VERSION ""
NS_ :

BS_:

BU_: Debug Boot INVR PDM FSM DIM BMS INVL DCM DEBUG

BO_ 701 Debug_CanMode: 1 Debug
SG_ Debug_EnableDebugMode : 0|1@1+ (1,0) [0|1] "" DEBUG,PDM,FSM,DIM,BMS,DCM

BO_ 702 Debug_Charging: 1 Debug
SG_ Debug_StartCharging : 0|1@1+ (1,0) [0|1] "" DEBUG,BMS

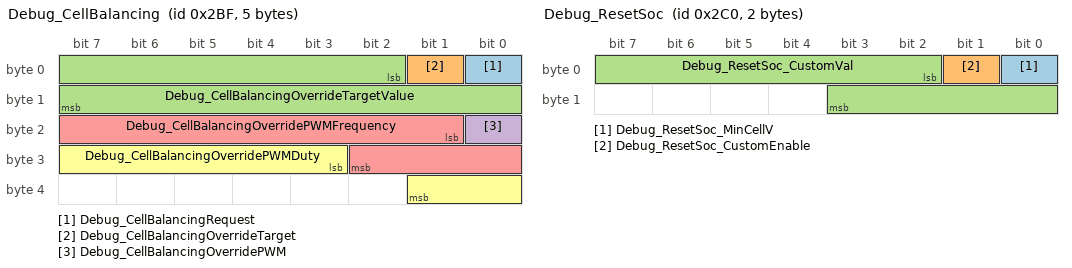
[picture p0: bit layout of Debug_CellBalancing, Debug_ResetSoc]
BO_ 703 Debug_CellBalancing: 5 Debug
SG_ Debug_CellBalancingRequest : 0|1@1+ (1,0) [0|1] "" DEBUG,BMS
SG_ Debug_CellBalancingOverrideTarget : 1|1@1+ (1,0) [0|1] "" DEBUG,BMS
SG_ Debug_CellBalancingOverrideTargetValue : 2|14@1+ (0.0001,3) [3|4.2] "V" DEBUG,BMS
SG_ Debug_CellBalancingOverridePWM : 16|1@1+ (1,0) [0|1] "" DEBUG,BMS
SG_ Debug_CellBalancingOverridePWMFrequency : 17|10@1+ (0.1,0) [0|100] "Hz" DEBUG,BMS
SG_ Debug_CellBalancingOverridePWMDuty : 27|7@1+ (1,0) [0|100] "%" DEBUG,BMS

BO_ 704 Debug_ResetSoc: 2 Debug
SG_ Debug_ResetSoc_MinCellV : 0|1@1+ (1,0) [0|1] "" DEBUG,BMS
SG_ Debug_ResetSoc_CustomEnable : 1|1@1+ (1,0) [0|1] "" DEBUG,BMS
SG_ Debug_ResetSoc_CustomVal : 2|10@1+ (0.1,0) [0|100] "%" DEBUG,BMS

BO_ 1109 Boot_BMS: 1 Boot
SG_ Boot_BMS_Status : 0|2@1+ (1,0) [0|2] "" DEBUG

BO_ 1119 Boot_DCM: 1 Boot
SG_ Boot_DCM_Status : 0|2@1+ (1,0) [0|2] "" DEBUG

BO_ 1129 Boot_FSM: 1 Boot
SG_ Boot_FSM_Status : 0|2@1+ (1,0) [0|2] "" DEBUG

BO_ 1139 Boot_PDM: 1 Boot
SG_ Boot_PDM_Status : 0|2@1+ (1,0) [0|2] "" DEBUG

BO_ 1149 Boot_DIM: 1 Boot
SG_ Boot_DIM_Status : 0|2@1+ (1,0) [0|2] "" DEBUG

BO_ 1309 Boot_H7Dev: 1 Boot
SG_ Boot_H7Dev_Status : 0|2@1+ (1,0) [0|2] "" DEBUG

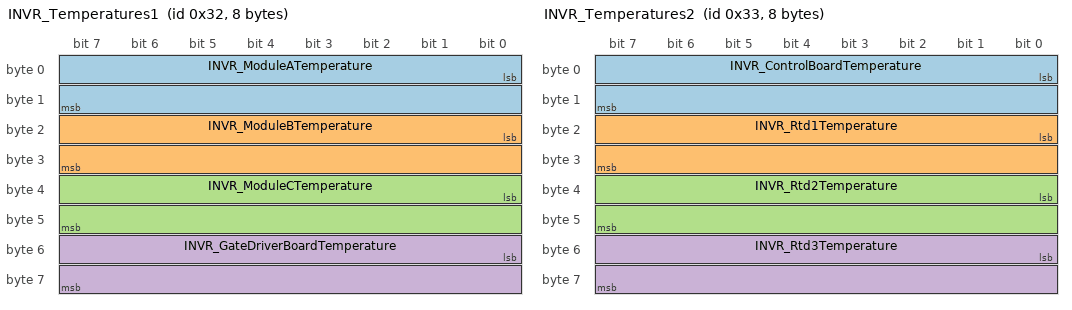
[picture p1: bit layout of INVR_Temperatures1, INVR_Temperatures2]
BO_ 50 INVR_Temperatures1: 8 INVR
SG_ INVR_ModuleATemperature : 0|16@1- (0.1,0) [-3276.8|3276.7] "degC" DEBUG,DIM
SG_ INVR_ModuleBTemperature : 16|16@1- (0.1,0) [-3276.8|3276.7] "degC" DEBUG,DIM
SG_ INVR_ModuleCTemperature : 32|16@1- (0.1,0) [-3276.8|3276.7] "degC" DEBUG,DIM
SG_ INVR_GateDriverBoardTemperature : 48|16@1- (0.1,0) [-3276.8|3276.7] "degC" DEBUG,DIM

BO_ 51 INVR_Temperatures2: 8 INVR
SG_ INVR_ControlBoardTemperature : 0|16@1- (0.1,0) [-3276.8|3276.7] "degC" DEBUG
SG_ INVR_Rtd1Temperature : 16|16@1- (0.1,0) [-3276.8|3276.7] "degC" DEBUG
SG_ INVR_Rtd2Temperature : 32|16@1- (0.1,0) [-3276.8|3276.7] "degC" DEBUG
SG_ INVR_Rtd3Temperature : 48|16@1- (0.1,0) [-3276.8|3276.7] "degC" DEBUG

BO_ 52 INVR_Temperatures3: 8 INVR
SG_ INVR_Rtd4Temperature : 0|16@1- (0.1,0) [-3276.8|3276.7] "degC" DEBUG,DCM
SG_ INVR_Rtd5Temperature : 16|16@1- (0.1,0) [-3276.8|3276.7] "degC" DEBUG,DCM
SG_ INVR_MotorTemperature : 32|16@1- (0.1,0) [-3276.8|3276.7] "degC" DEBUG,DCM
SG_ INVR_TorqueShudder : 48|16@1- (0.1,0) [-3276.8|3276.7] "Nm" DEBUG,DCM

BO_ 55 INVR_MotorPositionInfo: 8 INVR
SG_ INVR_MotorAngle : 0|16@1- (0.1,0) [0.0|359.9] "deg" DEBUG,DIM,DCM
SG_ INVR_MotorSpeed : 16|16@1- (1,0) [-32768|32767] "rpm" DEBUG,DIM,DCM
SG_ INVR_ElectricalOutputFrequency : 32|16@1- (0.1,0) [-3276.8|3276.7] "hz" DEBUG,DIM,DCM
SG_ INVR_DeltaResolverFiltered : 48|16@1- (0.1,0) [0.0|359.9] "deg" DEBUG,DIM,DCM

BO_ 56 INVR_CurrentInfo: 8 INVR
SG_ INVR_PhaseACurrent : 0|16@1- (0.1,0) [-3276.8|3276.7] "A" DEBUG
SG_ INVR_PhaseBCurrent : 16|16@1- (0.1,0) [-3276.8|3276.7] "A" DEBUG
SG_ INVR_PhaseCCurrent : 32|16@1- (0.1,0) [-3276.8|3276.7] "A" DEBUG
SG_ INVR_DcBusCurrent : 48|16@1- (0.1,0) [-3276.8|3276.7] "A" DEBUG

BO_ 57 INVR_VoltageInfo: 8 INVR
SG_ INVR_DcBusVoltage : 0|16@1- (0.1,0) [-3276.8|3276.7] "V" DEBUG
SG_ INVR_OutputVoltage : 16|16@1- (0.1,0) [-3276.8|3276.7] "V" DEBUG
SG_ INVR_VAB_Vd_Voltage : 32|16@1- (0.1,0) [-3276.8|3276.7] "V" DEBUG
SG_ INVR_VBC_Vq_Voltage : 48|16@1- (0.1,0) [-3276.8|3276.7] "V" DEBUG

BO_ 59 INVR_InternalVoltages: 8 INVR
SG_ INVR_ReferenceVoltage_1V5 : 0|16@1- (0.01,0) [-327.68|327.67] "V" DEBUG
SG_ INVR_ReferenceVoltage_2V5 : 16|16@1- (0.01,0) [-327.68|327.67] "V" DEBUG
SG_ INVR_ReferenceVoltage_5V : 32|16@1- (0.01,0) [-327.68|327.67] "V" DEBUG
SG_ INVR_ReferenceVoltage_12V : 48|16@1- (0.01,0) [-327.68|327.67] "V" DEBUG

BO_ 60 INVR_InternalStates: 8 INVR
SG_ INVR_VsmState : 0|4@1+ (1,0) [0|15] "" DEBUG,DCM
SG_ INVR_PwmFrequency : 8|8@1+ (1,0) [0|255] "kHz" DEBUG,DCM
SG_ INVR_InverterState : 16|4@1+ (1,0) [0|9] "" DEBUG,DCM
SG_ INVR_Relay1State : 24|1@1+ (1,0) [0|1] "" DEBUG,DCM
SG_ INVR_Relay2State : 25|1@1+ (1,0) [0|1] "" DEBUG,DCM
SG_ INVR_Relay3State : 26|1@1+ (1,0) [0|1] "" DEBUG,DCM
SG_ INVR_Relay4State : 27|1@1+ (1,0) [0|1] "" DEBUG,DCM
SG_ INVR_Relay5State : 28|1@1+ (1,0) [0|1] "" DEBUG,DCM
SG_ INVR_Relay6State : 29|1@1+ (1,0) [0|1] "" DEBUG,DCM
SG_ INVR_InverterRunMode : 32|1@1+ (1,0) [0|1] "" DEBUG,DCM
SG_ INVR_InverterActiveDischargeState : 37|3@1+ (1,0) [0|4] "" DEBUG,DCM
SG_ INVR_InverterCommandMode : 40|1@1+ (1,0) [0|1] "" DEBUG,DCM
SG_ INVR_RollingCounter : 44|4@1+ (1,0) [0|15] "" DEBUG,DCM
SG_ INVR_InverterEnableState : 48|1@1+ (1,0) [0|1] "" DEBUG,DCM
SG_ INVR_StartModeActive : 54|1@1+ (1,0) [0|1] "" DEBUG,DCM
SG_ INVR_InverterLockoutEnabled : 55|1@1+ (1,0) [0|1] "" DEBUG,DCM
SG_ INVR_DirectionCommand : 56|1@1+ (1,0) [0|1] "" DEBUG,DCM
SG_ INVR_BmsActive : 57|1@1+ (1,0) [0|1] "" DEBUG,DCM
SG_ INVR_BmsTorqueLimiting : 58|1@1+ (1,0) [0|1] "" DEBUG,DCM
SG_ INVR_MaxSpeedLimiting : 59|1@1+ (1,0) [0|1] "" DEBUG,DCM
SG_ INVR_HotSpotLimiting : 60|1@1+ (1,0) [0|1] "" DEBUG,DCM
SG_ INVR_LowSpeedLimiting : 61|1@1+ (1,0) [0|1] "" DEBUG,DCM
SG_ INVR_CoolantTemperatureLimiting : 62|1@1+ (1,0) [0|1] "" DEBUG,DCM

BO_ 61 INVR_FaultCodes: 8 INVR
SG_ INVR_Post_HardwareGateDesaturationFault : 0|1@1+ (1,0) [0|1] "" DEBUG
SG_ INVR_Post_HwOverCurrentFault : 1|1@1+ (1,0) [0|1] "" DEBUG
SG_ INVR_Post_AcceleratorShorted : 2|1@1+ (1,0) [0|1] "" DEBUG
SG_ INVR_Post_AcceleratorOpen : 3|1@1+ (1,0) [0|1] "" DEBUG
SG_ INVR_Post_CurrentSensorLow : 4|1@1+ (1,0) [0|1] "" DEBUG
SG_ INVR_Post_CurrentSensorHigh : 5|1@1+ (1,0) [0|1] "" DEBUG
SG_ INVR_Post_ModuleTempreatureLow : 6|1@1+ (1,0) [0|1] "" DEBUG
SG_ INVR_Post_ModuleTemperatureHigh : 7|1@1+ (1,0) [0|1] "" DEBUG
SG_ INVR_Post_ControlPcbTemperatureLow : 8|1@1+ (1,0) [0|1] "" DEBUG
SG_ INVR_Post_ControlPcbTemperatureHigh : 9|1@1+ (1,0) [0|1] "" DEBUG
SG_ INVR_Post_GateDrivePcbTemperatureLow : 10|1@1+ (1,0) [0|1] "" DEBUG
SG_ INVR_Post_GateDrivePcbTemperatureHigh : 11|1@1+ (1,0) [0|1] "" DEBUG
SG_ INVR_Post_5VSenseVoltageLow : 12|1@1+ (1,0) [0|1] "" DEBUG
SG_ INVR_Post_5VSenseVoltageHigh : 13|1@1+ (1,0) [0|1] "" DEBUG
SG_ INVR_Post_12VSenseVoltageLow : 14|1@1+ (1,0) [0|1] "" DEBUG
SG_ INVR_Post_12VSenseVoltageHigh : 15|1@1+ (1,0) [0|1] "" DEBUG
SG_ INVR_Post_2V5SenseVoltageLow : 16|1@1+ (1,0) [0|1] "" DEBUG
SG_ INVR_Post_2V5SenseVoltageHigh : 17|1@1+ (1,0) [0|1] "" DEBUG
SG_ INVR_Post_1V5SenseVoltageLow : 18|1@1+ (1,0) [0|1] "" DEBUG
SG_ INVR_Post_1V5SenseVoltageHigh : 19|1@1+ (1,0) [0|1] "" DEBUG
SG_ INVR_Post_DcBusVoltageHigh : 20|1@1+ (1,0) [0|1] "" DEBUG
SG_ INVR_Post_DcBusVoltageLow : 21|1@1+ (1,0) [0|1] "" DEBUG
SG_ INVR_Post_PrechargeTimeout : 22|1@1+ (1,0) [0|1] "" DEBUG
SG_ INVR_Post_PrechargeVoltageFailure : 23|1@1+ (1,0) [0|1] "" DEBUG
SG_ INVR_Post_EepromChecksumInvalid : 24|1@1+ (1,0) [0|1] "" DEBUG
SG_ INVR_Post_EepromDataOutOfRange : 25|1@1+ (1,0) [0|1] "" DEBUG
SG_ INVR_Post_EepromUpdateRequired : 26|1@1+ (1,0) [0|1] "" DEBUG
SG_ INVR_Post_HardwareDcBusOverVoltageDuringInitialization : 27|1@1+ (1,0) [0|1] "" DEBUG
SG_ INVR_Post_GateDriverInitialization : 28|1@1+ (1,0) [0|1] "" DEBUG
SG_ INVR_Post_BrakeShorted : 30|1@1+ (1,0) [0|1] "" DEBUG
SG_ INVR_Post_BrakeOpen : 31|1@1+ (1,0) [0|1] "" DEBUG
SG_ INVR_Run_MotorOverSpeedFault : 32|1@1+ (1,0) [0|1] "" DEBUG
SG_ INVR_Run_OverCurrentFault : 33|1@1+ (1,0) [0|1] "" DEBUG
SG_ INVR_Run_OverVoltageFault : 34|1@1+ (1,0) [0|1] "" DEBUG
SG_ INVR_Run_InverterOverTemperatureFault : 35|1@1+ (1,0) [0|1] "" DEBUG
SG_ INVR_Run_AcceleratorInputShortedFault : 36|1@1+ (1,0) [0|1] "" DEBUG
SG_ INVR_Run_AcceleratorInputOpenFault : 37|1@1+ (1,0) [0|1] "" DEBUG
SG_ INVR_Run_DirectionCommandFault : 38|1@1+ (1,0) [0|1] "" DEBUG
SG_ INVR_Run_InverterResponseTimeoutFault : 39|1@1+ (1,0) [0|1] "" DEBUG
SG_ INVR_Run_HardwareGateDesaturationFault : 40|1@1+ (1,0) [0|1] "" DEBUG
SG_ INVR_Run_HardwareOverCurrentFault : 41|1@1+ (1,0) [0|1] "" DEBUG
SG_ INVR_Run_UnderVoltageFault : 42|1@1+ (1,0) [0|1] "" DEBUG
SG_ INVR_Run_CanCommandMessageLostFault : 43|1@1+ (1,0) [0|1] "" DEBUG
SG_ INVR_Run_MotorOverTemperature : 44|1@1+ (1,0) [0|1] "" DEBUG
SG_ INVR_Run_BrakeInputShortedFault : 48|1@1+ (1,0) [0|1] "" DEBUG
SG_ INVR_Run_BrakeInputOpenFault : 49|1@1+ (1,0) [0|1] "" DEBUG
SG_ INVR_Run_ModuleAOverTemperatureFault : 50|1@1+ (1,0) [0|1] "" DEBUG
SG_ INVR_Run_ModuleBOverTemperatureFault : 51|1@1+ (1,0) [0|1] "" DEBUG
SG_ INVR_Run_ModuleCOverTemperatureFault : 52|1@1+ (1,0) [0|1] "" DEBUG
SG_ INVR_Run_PcbOverTemperatureFault : 53|1@1+ (1,0) [0|1] "" DEBUG
SG_ INVR_Run_GateDriveBoard1OverTemperatureFault : 54|1@1+ (1,0) [0|1] "" DEBUG
SG_ INVR_Run_GateDriveBoard2OverTemperatureFault : 55|1@1+ (1,0) [0|1] "" DEBUG
SG_ INVR_Run_GateDriveBoard3OverTemperatureFault : 56|1@1+ (1,0) [0|1] "" DEBUG
SG_ INVR_Run_CurrentSensorFault : 57|1@1+ (1,0) [0|1] "" DEBUG
SG_ INVR_Run_GateDriverOverVoltage : 58|1@1+ (1,0) [0|1] "" DEBUG
SG_ INVR_Run_HardwareDcBusOverVoltageGen3 : 59|1@1+ (1,0) [0|1] "" DEBUG
SG_ INVR_Run_HardwareDcBusOverVoltageGen5 : 60|1@1+ (1,0) [0|1] "" DEBUG
SG_ INVR_Run_ResolverNotConnected : 62|1@1+ (1,0) [0|1] "" DEBUG

BO_ 62 INVR_TorqueAndTimerInfo: 8 INVR
SG_ INVR_CommandedTorque : 0|16@1- (0.1,0) [-3276.8|3276.7] "Nm" DEBUG
SG_ INVR_TorqueFeedback : 16|16@1- (0.1,0) [-3276.8|3276.7] "Nm" DEBUG
SG_ INVR_PowerOnTimer : 32|32@1+ (0.003,0) [0|12884900] "sec" DEBUG

BO_ 83 INVR_DebugReadWriteParamCommand: 6 INVR
SG_ INVR_CommandParameterAddress : 0|16@1+ (1,0) [0|65535] "" DEBUG
SG_ INVR_CommandReadWrite : 16|1@1+ (1,0) [0|1] "" DEBUG
SG_ INVR_CommandData : 32|16@1+ (1,0) [0|65535] "" DEBUG

BO_ 84 INVR_DebugReadWriteParamResponse: 6 INVR
SG_ INVR_ResponseParameterAddress : 0|16@1+ (1,0) [0|65535] "" DEBUG
SG_ INVR_ResponseWriteSuccess : 16|1@1+ (1,0) [0|1] "" DEBUG
SG_ INVR_ResponseData : 32|16@1+ (1,0) [0|65535] "" DEBUG

BO_ 402 PDM_Vitals: 1 PDM
SG_ PDM_Heartbeat : 0|1@1+ (1,0) [0|1] "" DEBUG,DIM,BMS
SG_ PDM_State : 1|1@1+ (1,0) [0|1] "" DEBUG,DIM,BMS

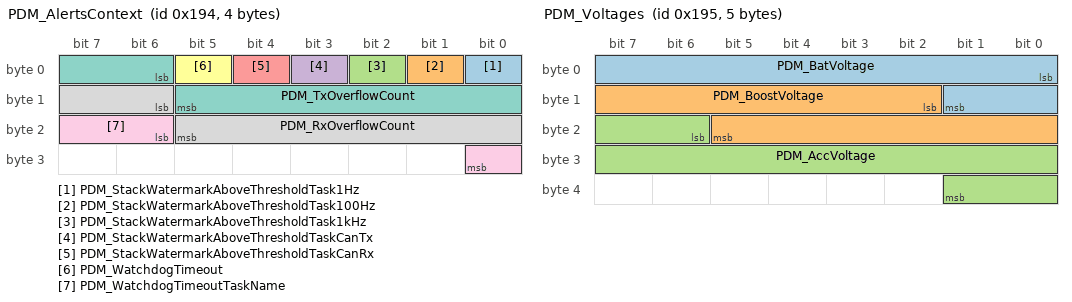
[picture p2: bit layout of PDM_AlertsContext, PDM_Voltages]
BO_ 404 PDM_AlertsContext: 4 PDM
SG_ PDM_StackWatermarkAboveThresholdTask1Hz : 0|1@1+ (1,0) [0|1] "" DEBUG
SG_ PDM_StackWatermarkAboveThresholdTask100Hz : 1|1@1+ (1,0) [0|1] "" DEBUG
SG_ PDM_StackWatermarkAboveThresholdTask1kHz : 2|1@1+ (1,0) [0|1] "" DEBUG
SG_ PDM_StackWatermarkAboveThresholdTaskCanTx : 3|1@1+ (1,0) [0|1] "" DEBUG
SG_ PDM_StackWatermarkAboveThresholdTaskCanRx : 4|1@1+ (1,0) [0|1] "" DEBUG
SG_ PDM_WatchdogTimeout : 5|1@1+ (1,0) [0|1] "" DEBUG
SG_ PDM_TxOverflowCount : 6|8@1+ (1,0) [0|255] "" DEBUG
SG_ PDM_RxOverflowCount : 14|8@1+ (1,0) [0|255] "" DEBUG
SG_ PDM_WatchdogTimeoutTaskName : 22|3@1+ (1,0) [0|4] "" DEBUG

BO_ 405 PDM_Voltages: 5 PDM
SG_ PDM_BatVoltage : 0|10@1+ (0.01,0) [0|10] "V" DEBUG
SG_ PDM_BoostVoltage : 10|12@1+ (0.01,0) [0|30] "V" DEBUG
SG_ PDM_AccVoltage : 22|12@1+ (0.01,0) [0|30] "V" DEBUG

BO_ 406 PDM_CommitInfo: 5 PDM
SG_ PDM_Hash : 0|32@1+ (1,0) [0|4294967295] "" DEBUG
SG_ PDM_Clean : 32|1@1+ (1,0) [0|1] "" DEBUG

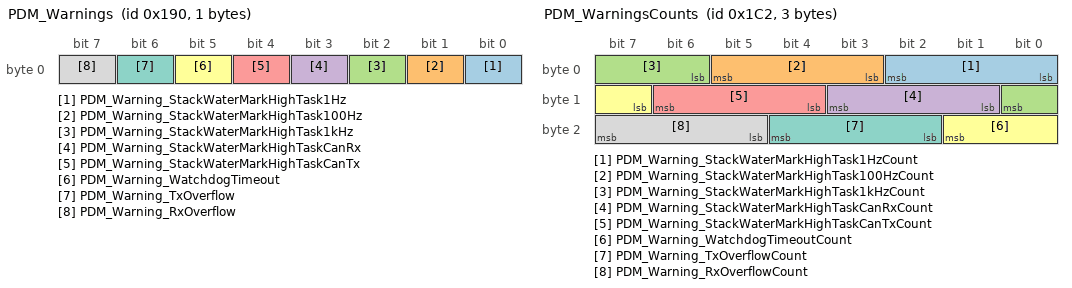
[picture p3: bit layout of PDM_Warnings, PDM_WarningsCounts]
BO_ 400 PDM_Warnings: 1 PDM
SG_ PDM_Warning_StackWaterMarkHighTask1Hz : 0|1@1+ (1,0) [0|1] "" DEBUG,Debug,Boot,INVR,FSM,DIM,BMS,INVL,DCM,DIM
SG_ PDM_Warning_StackWaterMarkHighTask100Hz : 1|1@1+ (1,0) [0|1] "" DEBUG,Debug,Boot,INVR,FSM,DIM,BMS,INVL,DCM,DIM
SG_ PDM_Warning_StackWaterMarkHighTask1kHz : 2|1@1+ (1,0) [0|1] "" DEBUG,Debug,Boot,INVR,FSM,DIM,BMS,INVL,DCM,DIM
SG_ PDM_Warning_StackWaterMarkHighTaskCanRx : 3|1@1+ (1,0) [0|1] "" DEBUG,Debug,Boot,INVR,FSM,DIM,BMS,INVL,DCM,DIM
SG_ PDM_Warning_StackWaterMarkHighTaskCanTx : 4|1@1+ (1,0) [0|1] "" DEBUG,Debug,Boot,INVR,FSM,DIM,BMS,INVL,DCM,DIM
SG_ PDM_Warning_WatchdogTimeout : 5|1@1+ (1,0) [0|1] "" DEBUG,Debug,Boot,INVR,FSM,DIM,BMS,INVL,DCM,DIM
SG_ PDM_Warning_TxOverflow : 6|1@1+ (1,0) [0|1] "" DEBUG,Debug,Boot,INVR,FSM,DIM,BMS,INVL,DCM,DIM
SG_ PDM_Warning_RxOverflow : 7|1@1+ (1,0) [0|1] "" DEBUG,Debug,Boot,INVR,FSM,DIM,BMS,INVL,DCM,DIM

BO_ 401 PDM_Faults: 1 PDM
SG_ PDM_Fault_DummyFault : 0|1@1+ (1,0) [0|1] "" DEBUG,Debug,Boot,INVR,FSM,DIM,BMS,INVL,DCM
SG_ PDM_Fault_MissingBMSHeartbeat : 1|1@1+ (1,0) [0|1] "" DEBUG,Debug,Boot,INVR,FSM,DIM,BMS,INVL,DCM

BO_ 450 PDM_WarningsCounts: 3 PDM
SG_ PDM_Warning_StackWaterMarkHighTask1HzCount : 0|3@1+ (1,0) [0|7] "" DEBUG
SG_ PDM_Warning_StackWaterMarkHighTask100HzCount : 3|3@1+ (1,0) [0|7] "" DEBUG
SG_ PDM_Warning_StackWaterMarkHighTask1kHzCount : 6|3@1+ (1,0) [0|7] "" DEBUG
SG_ PDM_Warning_StackWaterMarkHighTaskCanRxCount : 9|3@1+ (1,0) [0|7] "" DEBUG
SG_ PDM_Warning_StackWaterMarkHighTaskCanTxCount : 12|3@1+ (1,0) [0|7] "" DEBUG
SG_ PDM_Warning_WatchdogTimeoutCount : 15|3@1+ (1,0) [0|7] "" DEBUG
SG_ PDM_Warning_TxOverflowCount : 18|3@1+ (1,0) [0|7] "" DEBUG
SG_ PDM_Warning_RxOverflowCount : 21|3@1+ (1,0) [0|7] "" DEBUG

BO_ 451 PDM_FaultsCounts: 1 PDM
SG_ PDM_Fault_DummyFaultCount : 0|3@1+ (1,0) [0|7] "" DEBUG
SG_ PDM_Fault_MissingBMSHeartbeatCount : 3|3@1+ (1,0) [0|7] "" DEBUG

BO_ 304 FSM_Vitals: 1 FSM
SG_ FSM_Heartbeat : 0|1@1+ (1,0) [0|1] "" DEBUG,DIM,BMS,DCM

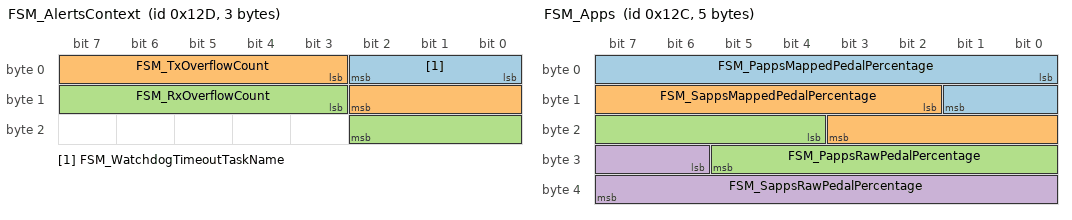
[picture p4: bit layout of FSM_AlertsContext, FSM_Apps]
BO_ 301 FSM_AlertsContext: 3 FSM
SG_ FSM_WatchdogTimeoutTaskName : 0|3@1+ (1,0) [0|4] "" DEBUG
SG_ FSM_TxOverflowCount : 3|8@1+ (1,0) [0|255] "" DEBUG
SG_ FSM_RxOverflowCount : 11|8@1+ (1,0) [0|255] "" DEBUG

BO_ 300 FSM_Apps: 5 FSM
SG_ FSM_PappsMappedPedalPercentage : 0|10@1+ (0.1,0) [0|100] "%" DEBUG,DIM,DCM
SG_ FSM_SappsMappedPedalPercentage : 10|10@1+ (0.1,0) [0|100] "%" DEBUG,DIM,DCM
SG_ FSM_PappsRawPedalPercentage : 20|10@1+ (0.1,0) [0|100] "%" DEBUG,DIM,DCM
SG_ FSM_SappsRawPedalPercentage : 30|10@1+ (0.1,0) [0|100] "%" DEBUG,DIM,DCM

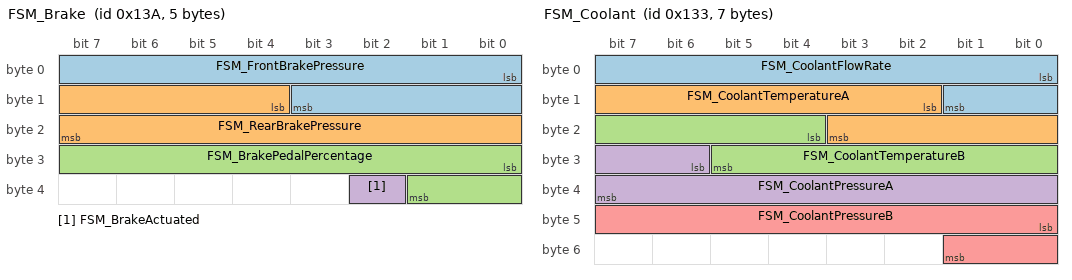
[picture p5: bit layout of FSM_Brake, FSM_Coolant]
BO_ 314 FSM_Brake: 5 FSM
SG_ FSM_FrontBrakePressure : 0|12@1+ (1,0) [0|2500] "psi" DEBUG,DCM
SG_ FSM_RearBrakePressure : 12|12@1+ (1,0) [0|2500] "psi" DEBUG,DCM
SG_ FSM_BrakePedalPercentage : 24|10@1+ (0.1,0) [0|100] "%" DEBUG,DCM
SG_ FSM_BrakeActuated : 34|1@1+ (1,0) [0|1] "" DEBUG,DCM

BO_ 307 FSM_Coolant: 7 FSM
SG_ FSM_CoolantFlowRate : 0|10@1+ (0.1,0) [0|100] "L/min" DEBUG
SG_ FSM_CoolantTemperatureA : 10|10@1+ (0.1,0) [0|100] "°C" DEBUG
SG_ FSM_CoolantTemperatureB : 20|10@1+ (0.1,0) [0|100] "°C" DEBUG
SG_ FSM_CoolantPressureA : 30|10@1+ (0.1,0) [0|100] "psi" DEBUG
SG_ FSM_CoolantPressureB : 40|10@1+ (0.1,0) [0|100] "psi" DEBUG

BO_ 318 FSM_Steering: 2 FSM
SG_ FSM_SteeringAngle : 0|12@1+ (0.1,-110) [-110|110] "deg" DEBUG,DCM

BO_ 317 FSM_Wheels: 3 FSM
SG_ FSM_LeftWheelSpeed : 0|11@1+ (0.1,0) [0|150] "km/h" DEBUG,DCM
SG_ FSM_RightWheelSpeed : 11|11@1+ (0.1,0) [0|150] "km/h" DEBUG,DCM

BO_ 319 FSM_CommitInfo: 5 FSM
SG_ FSM_Hash : 0|32@1+ (1,0) [0|4294967295] "" DEBUG
SG_ FSM_Clean : 32|1@1+ (1,0) [0|1] "" DEBUG

BO_ 350 FSM_Warnings: 3 FSM
SG_ FSM_Warning_StackWaterMarkHighTask1Hz : 0|1@1+ (1,0) [0|1] "" DEBUG,Debug,Boot,INVR,PDM,DIM,BMS,INVL,DCM,DIM
SG_ FSM_Warning_StackWaterMarkHighTask100Hz : 1|1@1+ (1,0) [0|1] "" DEBUG,Debug,Boot,INVR,PDM,DIM,BMS,INVL,DCM,DIM
SG_ FSM_Warning_StackWaterMarkHighTask1kHz : 2|1@1+ (1,0) [0|1] "" DEBUG,Debug,Boot,INVR,PDM,DIM,BMS,INVL,DCM,DIM
SG_ FSM_Warning_StackWaterMarkHighTaskCanRx : 3|1@1+ (1,0) [0|1] "" DEBUG,Debug,Boot,INVR,PDM,DIM,BMS,INVL,DCM,DIM
SG_ FSM_Warning_StackWaterMarkHighTaskCanTx : 4|1@1+ (1,0) [0|1] "" DEBUG,Debug,Boot,INVR,PDM,DIM,BMS,INVL,DCM,DIM
SG_ FSM_Warning_WatchdogTimeout : 5|1@1+ (1,0) [0|1] "" DEBUG,Debug,Boot,INVR,PDM,DIM,BMS,INVL,DCM,DIM
SG_ FSM_Warning_TxOverflow : 6|1@1+ (1,0) [0|1] "" DEBUG,Debug,Boot,INVR,PDM,DIM,BMS,INVL,DCM,DIM
SG_ FSM_Warning_RxOverflow : 7|1@1+ (1,0) [0|1] "" DEBUG,Debug,Boot,INVR,PDM,DIM,BMS,INVL,DCM,DIM
SG_ FSM_Warning_LeftWheelSpeedOutOfRange : 8|1@1+ (1,0) [0|1] "" DEBUG,Debug,Boot,INVR,PDM,DIM,BMS,INVL,DCM,DIM
SG_ FSM_Warning_RightWheelSpeedOutOfRange : 9|1@1+ (1,0) [0|1] "" DEBUG,Debug,Boot,INVR,PDM,DIM,BMS,INVL,DCM,DIM
SG_ FSM_Warning_SteeringAngleOCSC : 10|1@1+ (1,0) [0|1] "" DEBUG,Debug,Boot,INVR,PDM,DIM,BMS,INVL,DCM,DIM
SG_ FSM_Warning_SteeringAngleOutOfRange : 11|1@1+ (1,0) [0|1] "" DEBUG,Debug,Boot,INVR,PDM,DIM,BMS,INVL,DCM,DIM
SG_ FSM_Warning_FrontBrakePressureOutOfRange : 12|1@1+ (1,0) [0|1] "" DEBUG,Debug,Boot,INVR,PDM,DIM,BMS,INVL,DCM,DIM
SG_ FSM_Warning_RearBrakePressureOutOfRange : 13|1@1+ (1,0) [0|1] "" DEBUG,Debug,Boot,INVR,PDM,DIM,BMS,INVL,DCM,DIM
SG_ FSM_Warning_BrakePressureSensorOCSC : 14|1@1+ (1,0) [0|1] "" DEBUG,Debug,Boot,INVR,PDM,DIM,BMS,INVL,DCM,DIM
SG_ FSM_Warning_BrakePedalSensorOCSC : 15|1@1+ (1,0) [0|1] "" DEBUG,Debug,Boot,INVR,PDM,DIM,BMS,INVL,DCM,DIM
SG_ FSM_Warning_FlowRateOutOfRange : 16|1@1+ (1,0) [0|1] "" DEBUG,Debug,Boot,INVR,PDM,DIM,BMS,INVL,DCM,DIM
SG_ FSM_Warning_BrakeAppsDisagreement : 17|1@1+ (1,0) [0|1] "" DEBUG,Debug,Boot,INVR,PDM,DIM,BMS,INVL,DCM,DIM
SG_ FSM_Warning_AppsDisagreement : 18|1@1+ (1,0) [0|1] "" DEBUG,Debug,Boot,INVR,PDM,DIM,BMS,INVL,DCM,DIM

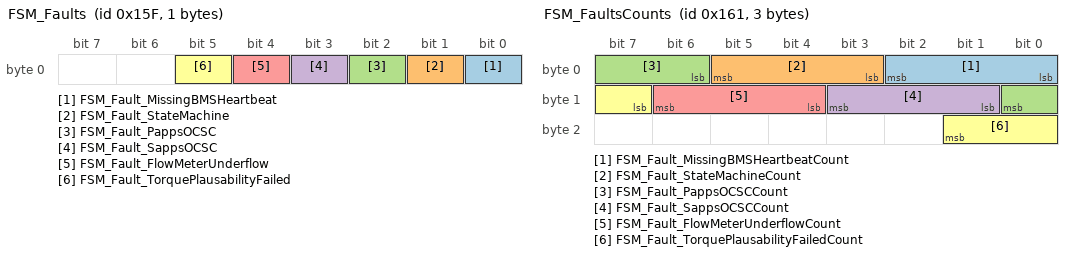
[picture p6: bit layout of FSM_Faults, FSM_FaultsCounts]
BO_ 351 FSM_Faults: 1 FSM
SG_ FSM_Fault_MissingBMSHeartbeat : 0|1@1+ (1,0) [0|1] "" DEBUG,Debug,Boot,INVR,PDM,DIM,BMS,INVL,DCM
SG_ FSM_Fault_StateMachine : 1|1@1+ (1,0) [0|1] "" DEBUG,Debug,Boot,INVR,PDM,DIM,BMS,INVL,DCM
SG_ FSM_Fault_PappsOCSC : 2|1@1+ (1,0) [0|1] "" DEBUG,Debug,Boot,INVR,PDM,DIM,BMS,INVL,DCM
SG_ FSM_Fault_SappsOCSC : 3|1@1+ (1,0) [0|1] "" DEBUG,Debug,Boot,INVR,PDM,DIM,BMS,INVL,DCM
SG_ FSM_Fault_FlowMeterUnderflow : 4|1@1+ (1,0) [0|1] "" DEBUG,Debug,Boot,INVR,PDM,DIM,BMS,INVL,DCM
SG_ FSM_Fault_TorquePlausabilityFailed : 5|1@1+ (1,0) [0|1] "" DEBUG,Debug,Boot,INVR,PDM,DIM,BMS,INVL,DCM

BO_ 352 FSM_WarningsCounts: 8 FSM
SG_ FSM_Warning_StackWaterMarkHighTask1HzCount : 0|3@1+ (1,0) [0|7] "" DEBUG
SG_ FSM_Warning_StackWaterMarkHighTask100HzCount : 3|3@1+ (1,0) [0|7] "" DEBUG
SG_ FSM_Warning_StackWaterMarkHighTask1kHzCount : 6|3@1+ (1,0) [0|7] "" DEBUG
SG_ FSM_Warning_StackWaterMarkHighTaskCanRxCount : 9|3@1+ (1,0) [0|7] "" DEBUG
SG_ FSM_Warning_StackWaterMarkHighTaskCanTxCount : 12|3@1+ (1,0) [0|7] "" DEBUG
SG_ FSM_Warning_WatchdogTimeoutCount : 15|3@1+ (1,0) [0|7] "" DEBUG
SG_ FSM_Warning_TxOverflowCount : 18|3@1+ (1,0) [0|7] "" DEBUG
SG_ FSM_Warning_RxOverflowCount : 21|3@1+ (1,0) [0|7] "" DEBUG
SG_ FSM_Warning_LeftWheelSpeedOutOfRangeCount : 24|3@1+ (1,0) [0|7] "" DEBUG
SG_ FSM_Warning_RightWheelSpeedOutOfRangeCount : 27|3@1+ (1,0) [0|7] "" DEBUG
SG_ FSM_Warning_SteeringAngleOCSCCount : 30|3@1+ (1,0) [0|7] "" DEBUG
SG_ FSM_Warning_SteeringAngleOutOfRangeCount : 33|3@1+ (1,0) [0|7] "" DEBUG
SG_ FSM_Warning_FrontBrakePressureOutOfRangeCount : 36|3@1+ (1,0) [0|7] "" DEBUG
SG_ FSM_Warning_RearBrakePressureOutOfRangeCount : 39|3@1+ (1,0) [0|7] "" DEBUG
SG_ FSM_Warning_BrakePressureSensorOCSCCount : 42|3@1+ (1,0) [0|7] "" DEBUG
SG_ FSM_Warning_BrakePedalSensorOCSCCount : 45|3@1+ (1,0) [0|7] "" DEBUG
SG_ FSM_Warning_FlowRateOutOfRangeCount : 48|3@1+ (1,0) [0|7] "" DEBUG
SG_ FSM_Warning_BrakeAppsDisagreementCount : 51|3@1+ (1,0) [0|7] "" DEBUG
SG_ FSM_Warning_AppsDisagreementCount : 54|3@1+ (1,0) [0|7] "" DEBUG

BO_ 353 FSM_FaultsCounts: 3 FSM
SG_ FSM_Fault_MissingBMSHeartbeatCount : 0|3@1+ (1,0) [0|7] "" DEBUG
SG_ FSM_Fault_StateMachineCount : 3|3@1+ (1,0) [0|7] "" DEBUG
SG_ FSM_Fault_PappsOCSCCount : 6|3@1+ (1,0) [0|7] "" DEBUG
SG_ FSM_Fault_SappsOCSCCount : 9|3@1+ (1,0) [0|7] "" DEBUG
SG_ FSM_Fault_FlowMeterUnderflowCount : 12|3@1+ (1,0) [0|7] "" DEBUG
SG_ FSM_Fault_TorquePlausabilityFailedCount : 15|3@1+ (1,0) [0|7] "" DEBUG

BO_ 502 DIM_Vitals: 1 DIM
SG_ DIM_Heartbeat : 0|1@1+ (1,0) [0|1] "" DEBUG,BMS,DCM

BO_ 503 DIM_Switches: 1 DIM
SG_ DIM_StartSwitch : 0|1@1+ (1,0) [0|1] "" DEBUG,DCM
SG_ DIM_AuxSwitch : 1|1@1+ (1,0) [0|1] "" DEBUG,DCM

BO_ 505 DIM_AlertsContext: 3 DIM
SG_ DIM_TxOverflowCount : 0|8@1+ (1,0) [0|255] "" DEBUG
SG_ DIM_RxOverflowCount : 8|8@1+ (1,0) [0|255] "" DEBUG
SG_ DIM_WatchdogTimeoutTaskName : 16|3@1+ (1,0) [0|4] "" DEBUG

BO_ 506 DIM_CommitInfo: 5 DIM
SG_ DIM_Hash : 0|32@1+ (1,0) [0|4294967295] "" DEBUG
SG_ DIM_Clean : 32|1@1+ (1,0) [0|1] "" DEBUG

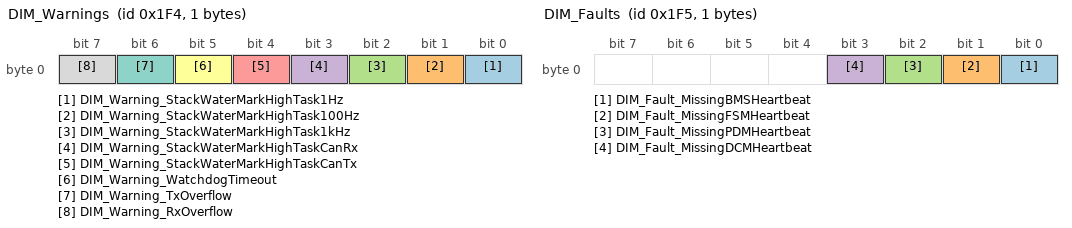
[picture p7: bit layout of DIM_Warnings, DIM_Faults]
BO_ 500 DIM_Warnings: 1 DIM
SG_ DIM_Warning_StackWaterMarkHighTask1Hz : 0|1@1+ (1,0) [0|1] "" DEBUG,Debug,Boot,INVR,PDM,FSM,BMS,INVL,DCM
SG_ DIM_Warning_StackWaterMarkHighTask100Hz : 1|1@1+ (1,0) [0|1] "" DEBUG,Debug,Boot,INVR,PDM,FSM,BMS,INVL,DCM
SG_ DIM_Warning_StackWaterMarkHighTask1kHz : 2|1@1+ (1,0) [0|1] "" DEBUG,Debug,Boot,INVR,PDM,FSM,BMS,INVL,DCM
SG_ DIM_Warning_StackWaterMarkHighTaskCanRx : 3|1@1+ (1,0) [0|1] "" DEBUG,Debug,Boot,INVR,PDM,FSM,BMS,INVL,DCM
SG_ DIM_Warning_StackWaterMarkHighTaskCanTx : 4|1@1+ (1,0) [0|1] "" DEBUG,Debug,Boot,INVR,PDM,FSM,BMS,INVL,DCM
SG_ DIM_Warning_WatchdogTimeout : 5|1@1+ (1,0) [0|1] "" DEBUG,Debug,Boot,INVR,PDM,FSM,BMS,INVL,DCM
SG_ DIM_Warning_TxOverflow : 6|1@1+ (1,0) [0|1] "" DEBUG,Debug,Boot,INVR,PDM,FSM,BMS,INVL,DCM
SG_ DIM_Warning_RxOverflow : 7|1@1+ (1,0) [0|1] "" DEBUG,Debug,Boot,INVR,PDM,FSM,BMS,INVL,DCM

BO_ 501 DIM_Faults: 1 DIM
SG_ DIM_Fault_MissingBMSHeartbeat : 0|1@1+ (1,0) [0|1] "" DEBUG,Debug,Boot,INVR,PDM,FSM,BMS,INVL,DCM
SG_ DIM_Fault_MissingFSMHeartbeat : 1|1@1+ (1,0) [0|1] "" DEBUG,Debug,Boot,INVR,PDM,FSM,BMS,INVL,DCM
SG_ DIM_Fault_MissingPDMHeartbeat : 2|1@1+ (1,0) [0|1] "" DEBUG,Debug,Boot,INVR,PDM,FSM,BMS,INVL,DCM
SG_ DIM_Fault_MissingDCMHeartbeat : 3|1@1+ (1,0) [0|1] "" DEBUG,Debug,Boot,INVR,PDM,FSM,BMS,INVL,DCM

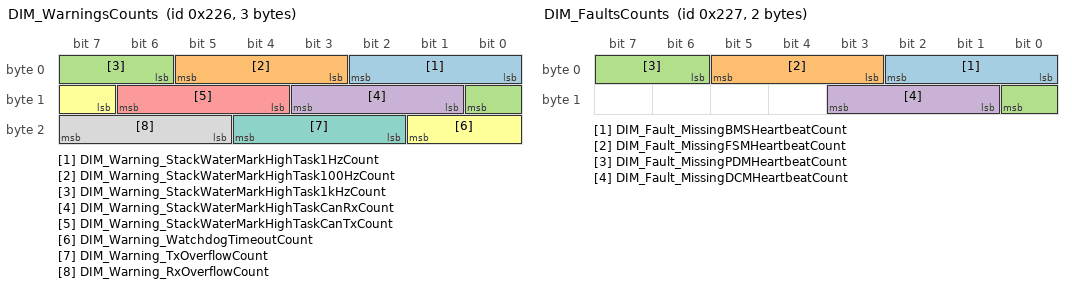
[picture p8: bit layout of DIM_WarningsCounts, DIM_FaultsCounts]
BO_ 550 DIM_WarningsCounts: 3 DIM
SG_ DIM_Warning_StackWaterMarkHighTask1HzCount : 0|3@1+ (1,0) [0|7] "" DEBUG
SG_ DIM_Warning_StackWaterMarkHighTask100HzCount : 3|3@1+ (1,0) [0|7] "" DEBUG
SG_ DIM_Warning_StackWaterMarkHighTask1kHzCount : 6|3@1+ (1,0) [0|7] "" DEBUG
SG_ DIM_Warning_StackWaterMarkHighTaskCanRxCount : 9|3@1+ (1,0) [0|7] "" DEBUG
SG_ DIM_Warning_StackWaterMarkHighTaskCanTxCount : 12|3@1+ (1,0) [0|7] "" DEBUG
SG_ DIM_Warning_WatchdogTimeoutCount : 15|3@1+ (1,0) [0|7] "" DEBUG
SG_ DIM_Warning_TxOverflowCount : 18|3@1+ (1,0) [0|7] "" DEBUG
SG_ DIM_Warning_RxOverflowCount : 21|3@1+ (1,0) [0|7] "" DEBUG

BO_ 551 DIM_FaultsCounts: 2 DIM
SG_ DIM_Fault_MissingBMSHeartbeatCount : 0|3@1+ (1,0) [0|7] "" DEBUG
SG_ DIM_Fault_MissingFSMHeartbeatCount : 3|3@1+ (1,0) [0|7] "" DEBUG
SG_ DIM_Fault_MissingPDMHeartbeatCount : 6|3@1+ (1,0) [0|7] "" DEBUG
SG_ DIM_Fault_MissingDCMHeartbeatCount : 9|3@1+ (1,0) [0|7] "" DEBUG

BO_ 100 BMS_Vitals: 1 BMS
SG_ BMS_Heartbeat : 0|1@1+ (1,0) [0|1] "" DEBUG,PDM,FSM,DIM,DCM
SG_ BMS_State : 1|3@1+ (1,0) [0|6] "" DEBUG,PDM,FSM,DIM,DCM

BO_ 104 BMS_AlertsContext: 3 BMS
SG_ BMS_TxOverflowCount : 0|8@1+ (1,0) [0|255] "" DEBUG
SG_ BMS_RxOverflowCount : 8|8@1+ (1,0) [0|255] "" DEBUG
SG_ BMS_WatchdogTimeoutTaskName : 16|3@1+ (1,0) [0|4] "" DEBUG

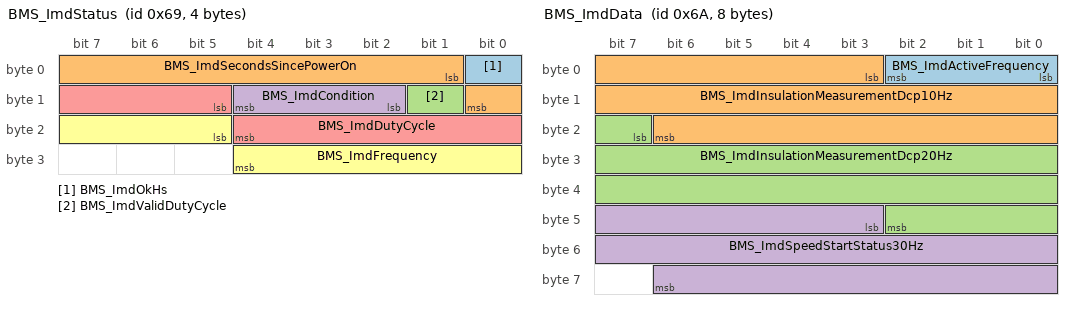
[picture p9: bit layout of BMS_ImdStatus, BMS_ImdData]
BO_ 105 BMS_ImdStatus: 4 BMS
SG_ BMS_ImdOkHs : 0|1@1+ (1,0) [0|1] "" DEBUG
SG_ BMS_ImdSecondsSincePowerOn : 1|8@1+ (1.0,0) [0|255] "Seconds" DEBUG
SG_ BMS_ImdValidDutyCycle : 9|1@1+ (1,0) [0|1] "" DEBUG
SG_ BMS_ImdCondition : 10|3@1+ (1,0) [0|6] "" DEBUG
SG_ BMS_ImdDutyCycle : 13|8@1+ (0.39215686274509803,0) [0|100] "%" DEBUG
SG_ BMS_ImdFrequency : 21|8@1+ (0.39215686274509803,0) [0|100] "Hz" DEBUG

BO_ 106 BMS_ImdData: 8 BMS
SG_ BMS_ImdActiveFrequency : 0|3@1+ (1,0) [0|5] "" DEBUG
SG_ BMS_ImdInsulationMeasurementDcp10Hz : 3|20@1+ (0.1,0) [0|65535] "kOhm" DEBUG
SG_ BMS_ImdInsulationMeasurementDcp20Hz : 23|20@1+ (0.1,0) [0|65535] "kOhm" DEBUG
SG_ BMS_ImdSpeedStartStatus30Hz : 43|20@1+ (0.1,0) [0|65535] "" DEBUG

BO_ 110 BMS_Charger: 1 BMS
SG_ BMS_ChargerConnected : 0|1@1+ (1,0) [0|1] "" DEBUG

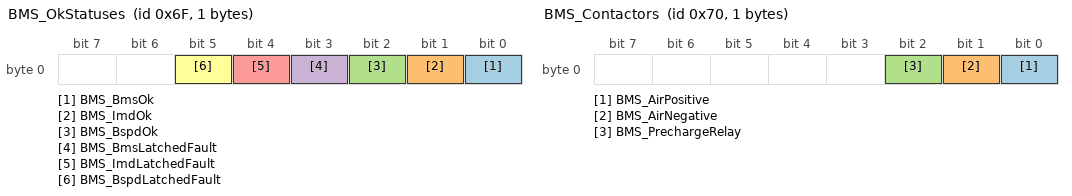
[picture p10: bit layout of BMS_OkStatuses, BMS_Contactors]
BO_ 111 BMS_OkStatuses: 1 BMS
SG_ BMS_BmsOk : 0|1@1+ (1,0) [0|1] "" DEBUG,DIM
SG_ BMS_ImdOk : 1|1@1+ (1,0) [0|1] "" DEBUG,DIM
SG_ BMS_BspdOk : 2|1@1+ (1,0) [0|1] "" DEBUG,DIM
SG_ BMS_BmsLatchedFault : 3|1@1+ (1,0) [0|1] "" DEBUG,DIM
SG_ BMS_ImdLatchedFault : 4|1@1+ (1,0) [0|1] "" DEBUG,DIM
SG_ BMS_BspdLatchedFault : 5|1@1+ (1,0) [0|1] "" DEBUG,DIM

BO_ 112 BMS_Contactors: 1 BMS
SG_ BMS_AirPositive : 0|1@1+ (1,0) [0|1] "" DEBUG,PDM,DIM
SG_ BMS_AirNegative : 1|1@1+ (1,0) [0|1] "" DEBUG,PDM,DIM
SG_ BMS_PrechargeRelay : 2|1@1+ (1,0) [0|1] "" DEBUG,PDM,DIM

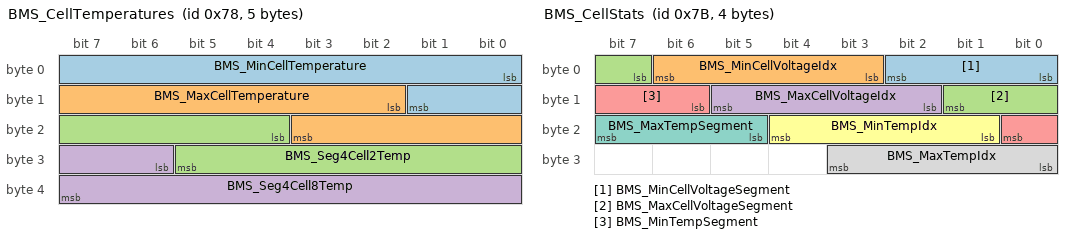
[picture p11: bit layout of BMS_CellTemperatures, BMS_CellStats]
BO_ 120 BMS_CellTemperatures: 5 BMS
SG_ BMS_MinCellTemperature : 0|10@1+ (0.1,0) [0|100] "degC" DEBUG,DCM
SG_ BMS_MaxCellTemperature : 10|10@1+ (0.1,0) [0|100] "degC" DEBUG,DCM
SG_ BMS_Seg4Cell2Temp : 20|10@1+ (0.1,0) [0|100] "degC" DEBUG,DCM
SG_ BMS_Seg4Cell8Temp : 30|10@1+ (0.1,0) [0|100] "degC" DEBUG,DCM

BO_ 121 BMS_CellVoltages: 4 BMS
SG_ BMS_MinCellVoltage : 0|16@1+ (0.0001,0) [0|5] "V" DEBUG,DIM,DCM
SG_ BMS_MaxCellVoltage : 16|16@1+ (0.0001,0) [0|5] "V" DEBUG,DIM,DCM

BO_ 122 BMS_StateOfCharge: 2 BMS
SG_ BMS_Soc : 0|10@1+ (0.1,0) [0|100] "%" DEBUG
SG_ BMS_SocCorrupt : 10|1@1+ (1,0) [0|1] "" DEBUG

BO_ 123 BMS_CellStats: 4 BMS
SG_ BMS_MinCellVoltageSegment : 0|3@1+ (1,0) [0|7] "" DEBUG
SG_ BMS_MinCellVoltageIdx : 3|4@1+ (1,0) [0|15] "" DEBUG
SG_ BMS_MaxCellVoltageSegment : 7|3@1+ (1.0,0) [0|7] "" DEBUG
SG_ BMS_MaxCellVoltageIdx : 10|4@1+ (1,0) [0|15] "" DEBUG
SG_ BMS_MinTempSegment : 14|3@1+ (1,0) [0|7] "" DEBUG
SG_ BMS_MinTempIdx : 17|4@1+ (1,0) [0|15] "" DEBUG
SG_ BMS_MaxTempSegment : 21|3@1+ (1,0) [0|7] "" DEBUG
SG_ BMS_MaxTempIdx : 24|4@1+ (1,0) [0|15] "" DEBUG

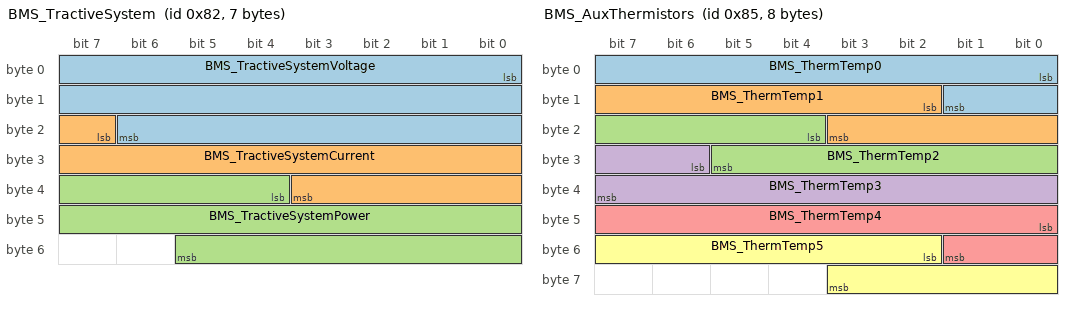
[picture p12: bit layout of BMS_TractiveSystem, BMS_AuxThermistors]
BO_ 130 BMS_TractiveSystem: 7 BMS
SG_ BMS_TractiveSystemVoltage : 0|23@1+ (0.0001,0) [0|600] "V" DEBUG,DIM,DCM
SG_ BMS_TractiveSystemCurrent : 23|13@1+ (0.1,-300) [-300|300] "A" DEBUG,DIM,DCM
SG_ BMS_TractiveSystemPower : 36|18@1+ (0.001,-100) [-100|100] "kW" DEBUG,DIM,DCM

BO_ 131 BMS_PackVoltage: 3 BMS
SG_ BMS_PackVoltage : 0|23@1+ (0.0001,0) [0|600] "V" DEBUG

BO_ 132 BMS_AvailablePower: 3 BMS
SG_ BMS_AvailablePower : 0|20@1+ (0.1,0) [0|100000] "W" DEBUG,DCM

BO_ 133 BMS_AuxThermistors: 8 BMS
SG_ BMS_ThermTemp0 : 0|10@1+ (0.1,0) [0|100] "degC" DEBUG
SG_ BMS_ThermTemp1 : 10|10@1+ (0.1,0) [0|100] "degC" DEBUG
SG_ BMS_ThermTemp2 : 20|10@1+ (0.1,0) [0|100] "degC" DEBUG
SG_ BMS_ThermTemp3 : 30|10@1+ (0.1,0) [0|100] "degC" DEBUG
SG_ BMS_ThermTemp4 : 40|10@1+ (0.1,0) [0|100] "degC" DEBUG
SG_ BMS_ThermTemp5 : 50|10@1+ (0.1,0) [0|100] "degC" DEBUG

BO_ 140 BMS_CommitInfo: 5 BMS
SG_ BMS_Hash : 0|32@1+ (1,0) [0|4294967295] "" DEBUG
SG_ BMS_Clean : 32|1@1+ (1,0) [0|1] "" DEBUG

BO_ 141 BMS_OWC_Segment0to2_Status: 6 BMS
SG_ BMS_Segment0_OWC_Cells_Status : 0|16@1+ (1,0) [0|65535] "" DEBUG
SG_ BMS_Segment1_OWC_Cells_Status : 16|16@1+ (1,0) [0|65535] "" DEBUG
SG_ BMS_Segment2_OWC_Cells_Status : 32|16@1+ (1,0) [0|65535] "" DEBUG

BO_ 142 BMS_OWC_Segment3to4_Status: 4 BMS
SG_ BMS_Segment3_OWC_Cells_Status : 0|16@1+ (1,0) [0|65535] "" DEBUG
SG_ BMS_Segment4_OWC_Cells_Status : 16|16@1+ (1,0) [0|65535] "" DEBUG

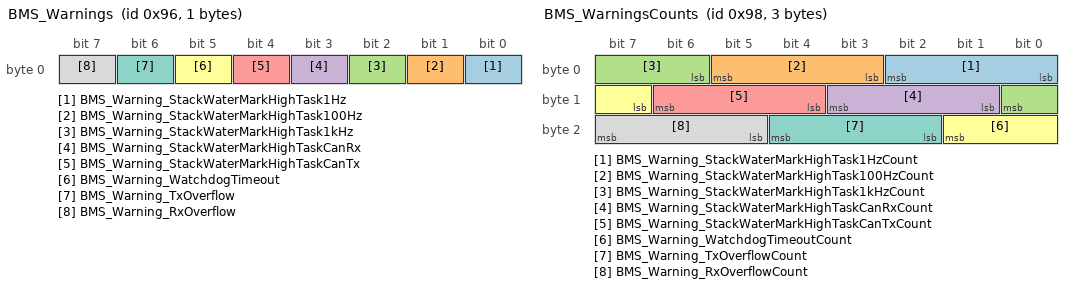
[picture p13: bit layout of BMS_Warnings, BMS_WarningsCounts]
BO_ 150 BMS_Warnings: 1 BMS
SG_ BMS_Warning_StackWaterMarkHighTask1Hz : 0|1@1+ (1,0) [0|1] "" DEBUG,Debug,Boot,INVR,PDM,FSM,DIM,INVL,DCM,DIM
SG_ BMS_Warning_StackWaterMarkHighTask100Hz : 1|1@1+ (1,0) [0|1] "" DEBUG,Debug,Boot,INVR,PDM,FSM,DIM,INVL,DCM,DIM
SG_ BMS_Warning_StackWaterMarkHighTask1kHz : 2|1@1+ (1,0) [0|1] "" DEBUG,Debug,Boot,INVR,PDM,FSM,DIM,INVL,DCM,DIM
SG_ BMS_Warning_StackWaterMarkHighTaskCanRx : 3|1@1+ (1,0) [0|1] "" DEBUG,Debug,Boot,INVR,PDM,FSM,DIM,INVL,DCM,DIM
SG_ BMS_Warning_StackWaterMarkHighTaskCanTx : 4|1@1+ (1,0) [0|1] "" DEBUG,Debug,Boot,INVR,PDM,FSM,DIM,INVL,DCM,DIM
SG_ BMS_Warning_WatchdogTimeout : 5|1@1+ (1,0) [0|1] "" DEBUG,Debug,Boot,INVR,PDM,FSM,DIM,INVL,DCM,DIM
SG_ BMS_Warning_TxOverflow : 6|1@1+ (1,0) [0|1] "" DEBUG,Debug,Boot,INVR,PDM,FSM,DIM,INVL,DCM,DIM
SG_ BMS_Warning_RxOverflow : 7|1@1+ (1,0) [0|1] "" DEBUG,Debug,Boot,INVR,PDM,FSM,DIM,INVL,DCM,DIM

BO_ 151 BMS_Faults: 3 BMS
SG_ BMS_Fault_MissingFSMHeartbeat : 0|1@1+ (1,0) [0|1] "" DEBUG,Debug,Boot,INVR,PDM,FSM,DIM,INVL,DCM
SG_ BMS_Fault_MissingDCMHeartbeat : 1|1@1+ (1,0) [0|1] "" DEBUG,Debug,Boot,INVR,PDM,FSM,DIM,INVL,DCM
SG_ BMS_Fault_MissingPDMHeartbeat : 2|1@1+ (1,0) [0|1] "" DEBUG,Debug,Boot,INVR,PDM,FSM,DIM,INVL,DCM
SG_ BMS_Fault_StateMachine : 3|1@1+ (1,0) [0|1] "" DEBUG,Debug,Boot,INVR,PDM,FSM,DIM,INVL,DCM
SG_ BMS_Fault_CellUndervoltage : 4|1@1+ (1,0) [0|1] "" DEBUG,Debug,Boot,INVR,PDM,FSM,DIM,INVL,DCM
SG_ BMS_Fault_CellOvervoltage : 5|1@1+ (1,0) [0|1] "" DEBUG,Debug,Boot,INVR,PDM,FSM,DIM,INVL,DCM
SG_ BMS_Fault_ModuleCommunicationError : 6|1@1+ (1,0) [0|1] "" DEBUG,Debug,Boot,INVR,PDM,FSM,DIM,INVL,DCM
SG_ BMS_Fault_CellUndertemp : 7|1@1+ (1,0) [0|1] "" DEBUG,Debug,Boot,INVR,PDM,FSM,DIM,INVL,DCM
SG_ BMS_Fault_CellOvertemp : 8|1@1+ (1,0) [0|1] "" DEBUG,Debug,Boot,INVR,PDM,FSM,DIM,INVL,DCM
SG_ BMS_Fault_Charger : 9|1@1+ (1,0) [0|1] "" DEBUG,Debug,Boot,INVR,PDM,FSM,DIM,INVL,DCM
SG_ BMS_Fault_ChargerDisconnectedDuringCharge : 10|1@1+ (1,0) [0|1] "" DEBUG,Debug,Boot,INVR,PDM,FSM,DIM,INVL,DCM
SG_ BMS_Fault_ChargerExternalShutdown : 11|1@1+ (1,0) [0|1] "" DEBUG,Debug,Boot,INVR,PDM,FSM,DIM,INVL,DCM
SG_ BMS_Fault_TractiveSystemOvercurrent : 12|1@1+ (1,0) [0|1] "" DEBUG,Debug,Boot,INVR,PDM,FSM,DIM,INVL,DCM
SG_ BMS_Fault_PrechargeFailure : 13|1@1+ (1,0) [0|1] "" DEBUG,Debug,Boot,INVR,PDM,FSM,DIM,INVL,DCM
SG_ BMS_Fault_OpenWireCheckFault : 14|1@1+ (1,0) [0|1] "" DEBUG,Debug,Boot,INVR,PDM,FSM,DIM,INVL,DCM
SG_ BMS_Fault_OpenWireCheck_Segment0_GND : 15|1@1+ (1,0) [0|1] "" DEBUG,Debug,Boot,INVR,PDM,FSM,DIM,INVL,DCM
SG_ BMS_Fault_OpenWireCheck_Segment1_GND : 16|1@1+ (1,0) [0|1] "" DEBUG,Debug,Boot,INVR,PDM,FSM,DIM,INVL,DCM
SG_ BMS_Fault_OpenWireCheck_Segment2_GND : 17|1@1+ (1,0) [0|1] "" DEBUG,Debug,Boot,INVR,PDM,FSM,DIM,INVL,DCM
SG_ BMS_Fault_OpenWireCheck_Segment3_GND : 18|1@1+ (1,0) [0|1] "" DEBUG,Debug,Boot,INVR,PDM,FSM,DIM,INVL,DCM
SG_ BMS_Fault_OpenWireCheck_Segment4_GND : 19|1@1+ (1,0) [0|1] "" DEBUG,Debug,Boot,INVR,PDM,FSM,DIM,INVL,DCM

BO_ 152 BMS_WarningsCounts: 3 BMS
SG_ BMS_Warning_StackWaterMarkHighTask1HzCount : 0|3@1+ (1,0) [0|7] "" DEBUG
SG_ BMS_Warning_StackWaterMarkHighTask100HzCount : 3|3@1+ (1,0) [0|7] "" DEBUG
SG_ BMS_Warning_StackWaterMarkHighTask1kHzCount : 6|3@1+ (1,0) [0|7] "" DEBUG
SG_ BMS_Warning_StackWaterMarkHighTaskCanRxCount : 9|3@1+ (1,0) [0|7] "" DEBUG
SG_ BMS_Warning_StackWaterMarkHighTaskCanTxCount : 12|3@1+ (1,0) [0|7] "" DEBUG
SG_ BMS_Warning_WatchdogTimeoutCount : 15|3@1+ (1,0) [0|7] "" DEBUG
SG_ BMS_Warning_TxOverflowCount : 18|3@1+ (1,0) [0|7] "" DEBUG
SG_ BMS_Warning_RxOverflowCount : 21|3@1+ (1,0) [0|7] "" DEBUG

BO_ 153 BMS_FaultsCounts: 8 BMS
SG_ BMS_Fault_MissingFSMHeartbeatCount : 0|3@1+ (1,0) [0|7] "" DEBUG
SG_ BMS_Fault_MissingDCMHeartbeatCount : 3|3@1+ (1,0) [0|7] "" DEBUG
SG_ BMS_Fault_MissingPDMHeartbeatCount : 6|3@1+ (1,0) [0|7] "" DEBUG
SG_ BMS_Fault_StateMachineCount : 9|3@1+ (1,0) [0|7] "" DEBUG
SG_ BMS_Fault_CellUndervoltageCount : 12|3@1+ (1,0) [0|7] "" DEBUG
SG_ BMS_Fault_CellOvervoltageCount : 15|3@1+ (1,0) [0|7] "" DEBUG
SG_ BMS_Fault_ModuleCommunicationErrorCount : 18|3@1+ (1,0) [0|7] "" DEBUG
SG_ BMS_Fault_CellUndertempCount : 21|3@1+ (1,0) [0|7] "" DEBUG
SG_ BMS_Fault_CellOvertempCount : 24|3@1+ (1,0) [0|7] "" DEBUG
SG_ BMS_Fault_ChargerCount : 27|3@1+ (1,0) [0|7] "" DEBUG
SG_ BMS_Fault_ChargerDisconnectedDuringChargeCount : 30|3@1+ (1,0) [0|7] "" DEBUG
SG_ BMS_Fault_ChargerExternalShutdownCount : 33|3@1+ (1,0) [0|7] "" DEBUG
SG_ BMS_Fault_TractiveSystemOvercurrentCount : 36|3@1+ (1,0) [0|7] "" DEBUG
SG_ BMS_Fault_PrechargeFailureCount : 39|3@1+ (1,0) [0|7] "" DEBUG
SG_ BMS_Fault_OpenWireCheckFaultCount : 42|3@1+ (1,0) [0|7] "" DEBUG
SG_ BMS_Fault_OpenWireCheck_Segment0_GNDCount : 45|3@1+ (1,0) [0|7] "" DEBUG
SG_ BMS_Fault_OpenWireCheck_Segment1_GNDCount : 48|3@1+ (1,0) [0|7] "" DEBUG
SG_ BMS_Fault_OpenWireCheck_Segment2_GNDCount : 51|3@1+ (1,0) [0|7] "" DEBUG
SG_ BMS_Fault_OpenWireCheck_Segment3_GNDCount : 54|3@1+ (1,0) [0|7] "" DEBUG
SG_ BMS_Fault_OpenWireCheck_Segment4_GNDCount : 57|3@1+ (1,0) [0|7] "" DEBUG

BO_ 0 INVL_Temperatures1: 8 INVL
SG_ INVL_ModuleATemperature : 0|16@1- (0.1,0) [-3276.8|3276.7] "degC" DEBUG
SG_ INVL_ModuleBTemperature : 16|16@1- (0.1,0) [-3276.8|3276.7] "degC" DEBUG
SG_ INVL_ModuleCTemperature : 32|16@1- (0.1,0) [-3276.8|3276.7] "degC" DEBUG
SG_ INVL_GateDriverBoardTemperature : 48|16@1- (0.1,0) [-3276.8|3276.7] "degC" DEBUG

BO_ 1 INVL_Temperatures2: 8 INVL
SG_ INVL_ControlBoardTemperature : 0|16@1- (0.1,0) [-3276.8|3276.7] "degC" DEBUG
SG_ INVL_Rtd1Temperature : 16|16@1- (0.1,0) [-3276.8|3276.7] "degC" DEBUG
SG_ INVL_Rtd2Temperature : 32|16@1- (0.1,0) [-3276.8|3276.7] "degC" DEBUG
SG_ INVL_Rtd3Temperature : 48|16@1- (0.1,0) [-3276.8|3276.7] "degC" DEBUG

BO_ 2 INVL_Temperatures3: 8 INVL
SG_ INVL_Rtd4Temperature : 0|16@1- (0.1,0) [-3276.8|3276.7] "degC" DEBUG,DCM
SG_ INVL_Rtd5Temperature : 16|16@1- (0.1,0) [-3276.8|3276.7] "degC" DEBUG,DCM
SG_ INVL_MotorTemperature : 32|16@1- (0.1,0) [-3276.8|3276.7] "degC" DEBUG,DCM
SG_ INVL_TorqueShudder : 48|16@1- (0.1,0) [-3276.8|3276.7] "Nm" DEBUG,DCM

BO_ 5 INVL_MotorPositionInfo: 8 INVL
SG_ INVL_MotorAngle : 0|16@1- (0.1,0) [0.0|359.9] "deg" DEBUG,DIM,DCM
SG_ INVL_MotorSpeed : 16|16@1- (1,0) [-32768|32767] "rpm" DEBUG,DIM,DCM
SG_ INVL_ElectricalOutputFrequency : 32|16@1- (0.1,0) [-3276.8|3276.7] "hz" DEBUG,DIM,DCM
SG_ INVL_DeltaResolverFiltered : 48|16@1- (0.1,0) [0.0|359.9] "deg" DEBUG,DIM,DCM

BO_ 6 INVL_CurrentInfo: 8 INVL
SG_ INVL_PhaseACurrent : 0|16@1- (0.1,0) [-3276.8|3276.7] "A" DEBUG
SG_ INVL_PhaseBCurrent : 16|16@1- (0.1,0) [-3276.8|3276.7] "A" DEBUG
SG_ INVL_PhaseCCurrent : 32|16@1- (0.1,0) [-3276.8|3276.7] "A" DEBUG
SG_ INVL_DcBusCurrent : 48|16@1- (0.1,0) [-3276.8|3276.7] "A" DEBUG

BO_ 7 INVL_VoltageInfo: 8 INVL
SG_ INVL_DcBusVoltage : 0|16@1- (0.1,0) [-3276.8|3276.7] "V" DEBUG
SG_ INVL_OutputVoltage : 16|16@1- (0.1,0) [-3276.8|3276.7] "V" DEBUG
SG_ INVL_VAB_Vd_Voltage : 32|16@1- (0.1,0) [-3276.8|3276.7] "V" DEBUG
SG_ INVL_VBC_Vq_Voltage : 48|16@1- (0.1,0) [-3276.8|3276.7] "V" DEBUG

BO_ 9 INVL_InternalVoltages: 8 INVL
SG_ INVL_ReferenceVoltage_1V5 : 0|16@1- (0.01,0) [-327.68|327.67] "V" DEBUG
SG_ INVL_ReferenceVoltage_2V5 : 16|16@1- (0.01,0) [-327.68|327.67] "V" DEBUG
SG_ INVL_ReferenceVoltage_5V : 32|16@1- (0.01,0) [-327.68|327.67] "V" DEBUG
SG_ INVL_ReferenceVoltage_12V : 48|16@1- (0.01,0) [-327.68|327.67] "V" DEBUG

BO_ 10 INVL_InternalStates: 8 INVL
SG_ INVL_VsmState : 0|4@1+ (1,0) [0|15] "" DEBUG,DCM
SG_ INVL_PwmFrequency : 8|8@1+ (1,0) [0|255] "kHz" DEBUG,DCM
SG_ INVL_InverterState : 16|4@1+ (1,0) [0|9] "" DEBUG,DCM
SG_ INVL_Relay1State : 24|1@1+ (1,0) [0|1] "" DEBUG,DCM
SG_ INVL_Relay2State : 25|1@1+ (1,0) [0|1] "" DEBUG,DCM
SG_ INVL_Relay3State : 26|1@1+ (1,0) [0|1] "" DEBUG,DCM
SG_ INVL_Relay4State : 27|1@1+ (1,0) [0|1] "" DEBUG,DCM
SG_ INVL_Relay5State : 28|1@1+ (1,0) [0|1] "" DEBUG,DCM
SG_ INVL_Relay6State : 29|1@1+ (1,0) [0|1] "" DEBUG,DCM
SG_ INVL_InverterRunMode : 32|1@1+ (1,0) [0|1] "" DEBUG,DCM
SG_ INVL_InverterActiveDischargeState : 37|3@1+ (1,0) [0|4] "" DEBUG,DCM
SG_ INVL_InverterCommandMode : 40|1@1+ (1,0) [0|1] "" DEBUG,DCM
SG_ INVL_RollingCounter : 44|4@1+ (1,0) [0|15] "" DEBUG,DCM
SG_ INVL_InverterEnableState : 48|1@1+ (1,0) [0|1] "" DEBUG,DCM
SG_ INVL_StartModeActive : 54|1@1+ (1,0) [0|1] "" DEBUG,DCM
SG_ INVL_InverterLockoutEnabled : 55|1@1+ (1,0) [0|1] "" DEBUG,DCM
SG_ INVL_DirectionCommand : 56|1@1+ (1,0) [0|1] "" DEBUG,DCM
SG_ INVL_BmsActive : 57|1@1+ (1,0) [0|1] "" DEBUG,DCM
SG_ INVL_BmsTorqueLimiting : 58|1@1+ (1,0) [0|1] "" DEBUG,DCM
SG_ INVL_MaxSpeedLimiting : 59|1@1+ (1,0) [0|1] "" DEBUG,DCM
SG_ INVL_HotSpotLimiting : 60|1@1+ (1,0) [0|1] "" DEBUG,DCM
SG_ INVL_LowSpeedLimiting : 61|1@1+ (1,0) [0|1] "" DEBUG,DCM
SG_ INVL_CoolantTemperatureLimiting : 62|1@1+ (1,0) [0|1] "" DEBUG,DCM

BO_ 11 INVL_FaultCodes: 8 INVL
SG_ INVL_Post_HardwareGateDesaturationFault : 0|1@1+ (1,0) [0|1] "" DEBUG
SG_ INVL_Post_HwOverCurrentFault : 1|1@1+ (1,0) [0|1] "" DEBUG
SG_ INVL_Post_AcceleratorShorted : 2|1@1+ (1,0) [0|1] "" DEBUG
SG_ INVL_Post_AcceleratorOpen : 3|1@1+ (1,0) [0|1] "" DEBUG
SG_ INVL_Post_CurrentSensorLow : 4|1@1+ (1,0) [0|1] "" DEBUG
SG_ INVL_Post_CurrentSensorHigh : 5|1@1+ (1,0) [0|1] "" DEBUG
SG_ INVL_Post_ModuleTempreatureLow : 6|1@1+ (1,0) [0|1] "" DEBUG
SG_ INVL_Post_ModuleTemperatureHigh : 7|1@1+ (1,0) [0|1] "" DEBUG
SG_ INVL_Post_ControlPcbTemperatureLow : 8|1@1+ (1,0) [0|1] "" DEBUG
SG_ INVL_Post_ControlPcbTemperatureHigh : 9|1@1+ (1,0) [0|1] "" DEBUG
SG_ INVL_Post_GateDrivePcbTemperatureLow : 10|1@1+ (1,0) [0|1] "" DEBUG
SG_ INVL_Post_GateDrivePcbTemperatureHigh : 11|1@1+ (1,0) [0|1] "" DEBUG
SG_ INVL_Post_5VSenseVoltageLow : 12|1@1+ (1,0) [0|1] "" DEBUG
SG_ INVL_Post_5VSenseVoltageHigh : 13|1@1+ (1,0) [0|1] "" DEBUG
SG_ INVL_Post_12VSenseVoltageLow : 14|1@1+ (1,0) [0|1] "" DEBUG
SG_ INVL_Post_12VSenseVoltageHigh : 15|1@1+ (1,0) [0|1] "" DEBUG
SG_ INVL_Post_2V5SenseVoltageLow : 16|1@1+ (1,0) [0|1] "" DEBUG
SG_ INVL_Post_2V5SenseVoltageHigh : 17|1@1+ (1,0) [0|1] "" DEBUG
SG_ INVL_Post_1V5SenseVoltageLow : 18|1@1+ (1,0) [0|1] "" DEBUG
SG_ INVL_Post_1V5SenseVoltageHigh : 19|1@1+ (1,0) [0|1] "" DEBUG
SG_ INVL_Post_DcBusVoltageHigh : 20|1@1+ (1,0) [0|1] "" DEBUG
SG_ INVL_Post_DcBusVoltageLow : 21|1@1+ (1,0) [0|1] "" DEBUG
SG_ INVL_Post_PrechargeTimeout : 22|1@1+ (1,0) [0|1] "" DEBUG
SG_ INVL_Post_PrechargeVoltageFailure : 23|1@1+ (1,0) [0|1] "" DEBUG
SG_ INVL_Post_EepromChecksumInvalid : 24|1@1+ (1,0) [0|1] "" DEBUG
SG_ INVL_Post_EepromDataOutOfRange : 25|1@1+ (1,0) [0|1] "" DEBUG
SG_ INVL_Post_EepromUpdateRequired : 26|1@1+ (1,0) [0|1] "" DEBUG
SG_ INVL_Post_HardwareDcBusOverVoltageDuringInitialization : 27|1@1+ (1,0) [0|1] "" DEBUG
SG_ INVL_Post_GateDriverInitialization : 28|1@1+ (1,0) [0|1] "" DEBUG
SG_ INVL_Post_BrakeShorted : 30|1@1+ (1,0) [0|1] "" DEBUG
SG_ INVL_Post_BrakeOpen : 31|1@1+ (1,0) [0|1] "" DEBUG
SG_ INVL_Run_MotorOverSpeedFault : 32|1@1+ (1,0) [0|1] "" DEBUG
SG_ INVL_Run_OverCurrentFault : 33|1@1+ (1,0) [0|1] "" DEBUG
SG_ INVL_Run_OverVoltageFault : 34|1@1+ (1,0) [0|1] "" DEBUG
SG_ INVL_Run_InverterOverTemperatureFault : 35|1@1+ (1,0) [0|1] "" DEBUG
SG_ INVL_Run_AcceleratorInputShortedFault : 36|1@1+ (1,0) [0|1] "" DEBUG
SG_ INVL_Run_AcceleratorInputOpenFault : 37|1@1+ (1,0) [0|1] "" DEBUG
SG_ INVL_Run_DirectionCommandFault : 38|1@1+ (1,0) [0|1] "" DEBUG
SG_ INVL_Run_InverterResponseTimeoutFault : 39|1@1+ (1,0) [0|1] "" DEBUG
SG_ INVL_Run_HardwareGateDesaturationFault : 40|1@1+ (1,0) [0|1] "" DEBUG
SG_ INVL_Run_HardwareOverCurrentFault : 41|1@1+ (1,0) [0|1] "" DEBUG
SG_ INVL_Run_UnderVoltageFault : 42|1@1+ (1,0) [0|1] "" DEBUG
SG_ INVL_Run_CanCommandMessageLostFault : 43|1@1+ (1,0) [0|1] "" DEBUG
SG_ INVL_Run_MotorOverTemperature : 44|1@1+ (1,0) [0|1] "" DEBUG
SG_ INVL_Run_BrakeInputShortedFault : 48|1@1+ (1,0) [0|1] "" DEBUG
SG_ INVL_Run_BrakeInputOpenFault : 49|1@1+ (1,0) [0|1] "" DEBUG
SG_ INVL_Run_ModuleAOverTemperatureFault : 50|1@1+ (1,0) [0|1] "" DEBUG
SG_ INVL_Run_ModuleBOverTemperatureFault : 51|1@1+ (1,0) [0|1] "" DEBUG
SG_ INVL_Run_ModuleCOverTemperatureFault : 52|1@1+ (1,0) [0|1] "" DEBUG
SG_ INVL_Run_PcbOverTemperatureFault : 53|1@1+ (1,0) [0|1] "" DEBUG
SG_ INVL_Run_GateDriveBoard1OverTemperatureFault : 54|1@1+ (1,0) [0|1] "" DEBUG
SG_ INVL_Run_GateDriveBoard2OverTemperatureFault : 55|1@1+ (1,0) [0|1] "" DEBUG
SG_ INVL_Run_GateDriveBoard3OverTemperatureFault : 56|1@1+ (1,0) [0|1] "" DEBUG
SG_ INVL_Run_CurrentSensorFault : 57|1@1+ (1,0) [0|1] "" DEBUG
SG_ INVL_Run_GateDriverOverVoltage : 58|1@1+ (1,0) [0|1] "" DEBUG
SG_ INVL_Run_HardwareDcBusOverVoltageGen3 : 59|1@1+ (1,0) [0|1] "" DEBUG
SG_ INVL_Run_HardwareDcBusOverVoltageGen5 : 60|1@1+ (1,0) [0|1] "" DEBUG
SG_ INVL_Run_ResolverNotConnected : 62|1@1+ (1,0) [0|1] "" DEBUG

BO_ 12 INVL_TorqueAndTimerInfo: 8 INVL
SG_ INVL_CommandedTorque : 0|16@1- (0.1,0) [-3276.8|3276.7] "Nm" DEBUG
SG_ INVL_TorqueFeedback : 16|16@1- (0.1,0) [-3276.8|3276.7] "Nm" DEBUG
SG_ INVL_PowerOnTimer : 32|32@1+ (0.003,0) [0|12884900] "sec" DEBUG

BO_ 33 INVL_DebugReadWriteParamCommand: 6 INVL
SG_ INVL_CommandParameterAddress : 0|16@1+ (1,0) [0|65535] "" DEBUG
SG_ INVL_CommandReadWrite : 16|1@1+ (1,0) [0|1] "" DEBUG
SG_ INVL_CommandData : 32|16@1+ (1,0) [0|65535] "" DEBUG

BO_ 34 INVL_DebugReadWriteParamResponse: 6 INVL
SG_ INVL_ResponseParameterAddress : 0|16@1+ (1,0) [0|65535] "" DEBUG
SG_ INVL_ResponseWriteSuccess : 16|1@1+ (1,0) [0|1] "" DEBUG
SG_ INVL_ResponseData : 32|16@1+ (1,0) [0|65535] "" DEBUG

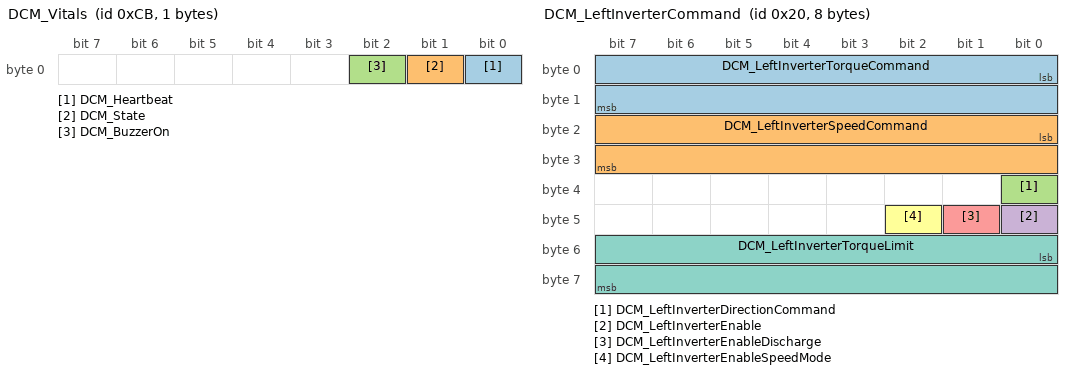
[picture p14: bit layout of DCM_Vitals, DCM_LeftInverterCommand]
BO_ 203 DCM_Vitals: 1 DCM
SG_ DCM_Heartbeat : 0|1@1+ (1,0) [0|1] "" DEBUG,FSM,DIM,BMS
SG_ DCM_State : 1|1@1+ (1,0) [0|1] "" DEBUG,FSM,DIM,BMS
SG_ DCM_BuzzerOn : 2|1@1+ (1,0) [0|1] "" DEBUG,FSM,DIM,BMS

BO_ 32 DCM_LeftInverterCommand: 8 DCM
SG_ DCM_LeftInverterTorqueCommand : 0|16@1- (0.1,0) [-3276.8|3276.7] "Nm" DEBUG,FSM,INVL
SG_ DCM_LeftInverterSpeedCommand : 16|16@1- (1,0) [-32768|32767] "rpm" DEBUG,FSM,INVL
SG_ DCM_LeftInverterDirectionCommand : 32|1@1+ (1,0) [0|1] "" DEBUG,FSM,INVL
SG_ DCM_LeftInverterEnable : 40|1@1+ (1,0) [0|1] "" DEBUG,FSM,INVL
SG_ DCM_LeftInverterEnableDischarge : 41|1@1+ (1,0) [0|1] "" DEBUG,FSM,INVL
SG_ DCM_LeftInverterEnableSpeedMode : 42|1@1+ (1,0) [0|1] "" DEBUG,FSM,INVL
SG_ DCM_LeftInverterTorqueLimit : 48|16@1- (0.1,0) [-3276.8|3276.7] "Nm" DEBUG,FSM,INVL

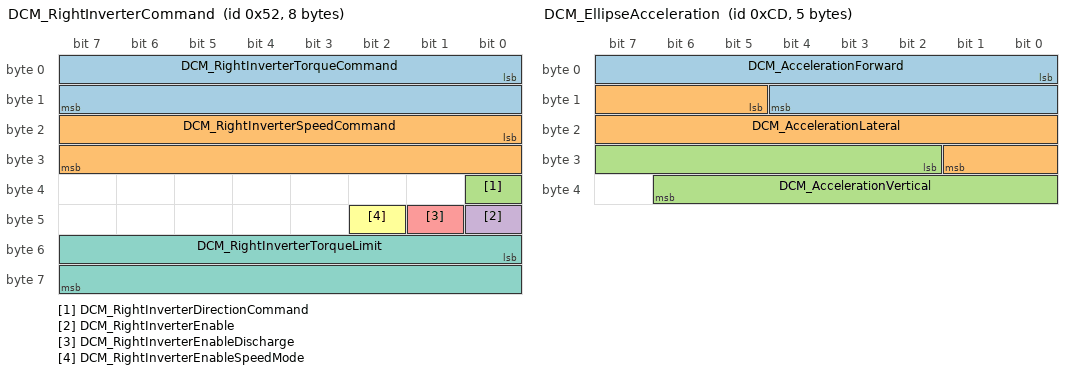
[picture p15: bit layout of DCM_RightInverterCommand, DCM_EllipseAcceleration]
BO_ 82 DCM_RightInverterCommand: 8 DCM
SG_ DCM_RightInverterTorqueCommand : 0|16@1- (0.1,0) [-3276.8|3276.7] "Nm" DEBUG,INVR,FSM
SG_ DCM_RightInverterSpeedCommand : 16|16@1- (1,0) [-32768|32767] "rpm" DEBUG,INVR,FSM
SG_ DCM_RightInverterDirectionCommand : 32|1@1+ (1,0) [0|1] "" DEBUG,INVR,FSM
SG_ DCM_RightInverterEnable : 40|1@1+ (1,0) [0|1] "" DEBUG,INVR,FSM
SG_ DCM_RightInverterEnableDischarge : 41|1@1+ (1,0) [0|1] "" DEBUG,INVR,FSM
SG_ DCM_RightInverterEnableSpeedMode : 42|1@1+ (1,0) [0|1] "" DEBUG,INVR,FSM
SG_ DCM_RightInverterTorqueLimit : 48|16@1- (0.1,0) [-3276.8|3276.7] "Nm" DEBUG,INVR,FSM

BO_ 204 DCM_AlertsContext: 3 DCM
SG_ DCM_TxOverflowCount : 0|8@1+ (1,0) [0|255] "" DEBUG
SG_ DCM_RxOverflowCount : 8|8@1+ (1,0) [0|255] "" DEBUG
SG_ DCM_WatchdogTimeoutTaskName : 16|3@1+ (1,0) [0|4] "" DEBUG

BO_ 208 DCM_EllipseStatus: 6 DCM
SG_ DCM_EllipseGeneralStatusBitmask : 0|16@1+ (1,0) [0|65535] "" DEBUG
SG_ DCM_EllipseComStatusBitmask : 16|32@1+ (1,0) [0|4294967295] "" DEBUG

BO_ 209 DCM_EllipseTime: 4 DCM
SG_ DCM_EllipseTimestamp : 0|32@1+ (1,0) [0|4294967295] "us" DEBUG

BO_ 205 DCM_EllipseAcceleration: 5 DCM
SG_ DCM_AccelerationForward : 0|13@1+ (0.01,-30) [-30|30] "m/s^2" DEBUG
SG_ DCM_AccelerationLateral : 13|13@1+ (0.01,-30) [-30|30] "m/s^2" DEBUG
SG_ DCM_AccelerationVertical : 26|13@1+ (0.01,-30) [-30|30] "m/s^2" DEBUG

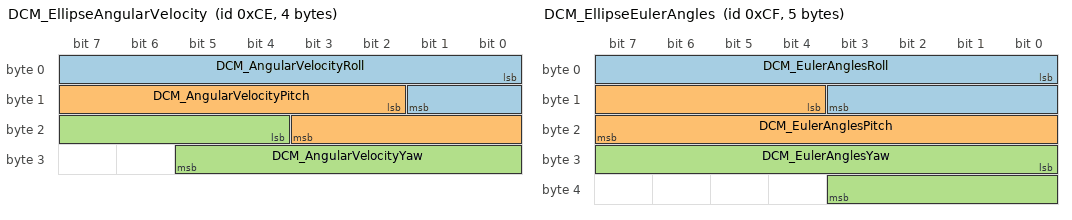
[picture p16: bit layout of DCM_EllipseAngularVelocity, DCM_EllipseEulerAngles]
BO_ 206 DCM_EllipseAngularVelocity: 4 DCM
SG_ DCM_AngularVelocityRoll : 0|10@1+ (1,-360) [-360|360] "deg/s" DEBUG
SG_ DCM_AngularVelocityPitch : 10|10@1+ (1,-360) [-360|360] "deg/s" DEBUG
SG_ DCM_AngularVelocityYaw : 20|10@1+ (1,-360) [-360|360] "deg/s" DEBUG

BO_ 207 DCM_EllipseEulerAngles: 5 DCM
SG_ DCM_EulerAnglesRoll : 0|12@1+ (0.1,-180) [-180|180] "deg" DEBUG
SG_ DCM_EulerAnglesPitch : 12|12@1+ (0.1,-180) [-180|180] "deg" DEBUG
SG_ DCM_EulerAnglesYaw : 24|12@1+ (0.1,-180) [-180|180] "deg" DEBUG

BO_ 210 DCM_CommitInfo: 5 DCM
SG_ DCM_Hash : 0|32@1+ (1,0) [0|4294967295] "" DEBUG
SG_ DCM_Clean : 32|1@1+ (1,0) [0|1] "" DEBUG

BO_ 211 DCM_PowerEstimate: 3 DCM
SG_ DCM_PowerEstimateValue : 0|11@1+ (0.1,0) [0|120] "" DEBUG
SG_ DCM_PowerEstimateMeasuredValue : 11|11@1+ (0.1,0) [0|120] "" DEBUG

BO_ 212 DCM_PowerEstimatePID: 8 DCM
SG_ DCM_PIDPowerEstimateOutput : 0|8@1- (0.01,0) [-1|1] "" DEBUG
SG_ DCM_PIDPowerEstimateError : 8|16@1- (0.1,0) [-80|80] "" DEBUG
SG_ DCM_PIDPowerEstimateDerivative : 24|16@1- (0.1,0) [-160|160] "" DEBUG
SG_ DCM_PIDPowerEstimateIntegral : 40|24@1- (0.1,0) [-21474836|21474836] "" DEBUG

BO_ 213 DCM_PIDSlipRatio: 8 DCM
SG_ DCM_PIDSlipRatioOutput : 0|8@1- (0.01,0) [-1|1] "" DEBUG
SG_ DCM_PIDSlipRatioError : 8|16@1- (0.1,0) [-80|80] "" DEBUG
SG_ DCM_PIDSlipRatioDerivative : 24|16@1- (0.1,0) [-160|160] "" DEBUG
SG_ DCM_PIDSlipRatioIntegral : 40|24@1- (0.1,0) [-21474836|21474836] "" DEBUG

BO_ 214 DCM_SlipRatios: 2 DCM
SG_ DCM_SlipRatioLeft : 0|8@1- (0.01,0) [-1|1] "" DEBUG
SG_ DCM_SlipRatioRight : 8|8@1- (0.01,0) [-1|1] "" DEBUG

BO_ 215 DCM_ActiveDiffOutputs: 3 DCM
SG_ DCM_ActiveDiffTorqueLeft : 0|10@1+ (0.1,0) [0|100] "" DEBUG
SG_ DCM_ActiveDiffTorqueRight : 10|10@1+ (0.1,0) [0|100] "" DEBUG

BO_ 216 DCM_PowerLimit: 3 DCM
SG_ DCM_PowerLimitValue : 0|11@1+ (0.1,0) [0|120] "" DEBUG
SG_ DCM_PowerLimitValueAtFullThrottle : 11|11@1+ (0.1,0) [0|120] "" DEBUG

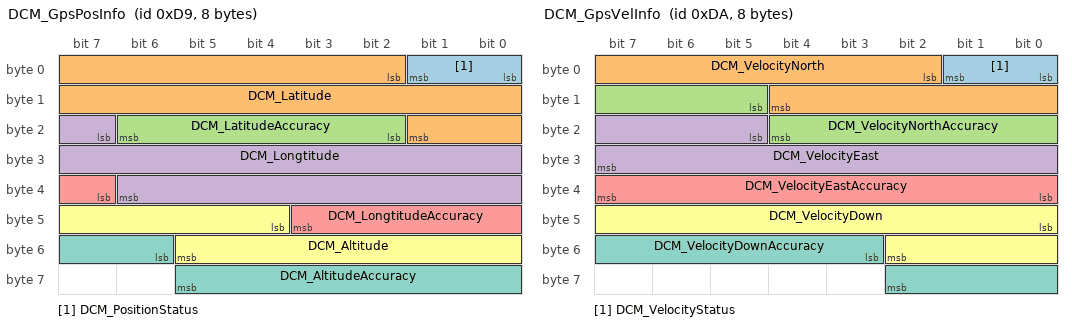
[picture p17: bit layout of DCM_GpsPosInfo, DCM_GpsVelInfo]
BO_ 217 DCM_GpsPosInfo: 8 DCM
SG_ DCM_PositionStatus : 0|2@1+ (1,0) [0|3] "" DEBUG
SG_ DCM_Latitude : 2|16@1+ (5e-05,47) [47|50] "deg" DEBUG
SG_ DCM_LatitudeAccuracy : 18|5@1+ (0.1,0) [0|2] "m" DEBUG
SG_ DCM_Longtitude : 23|16@1+ (5e-05,122) [122|125] "deg" DEBUG
SG_ DCM_LongtitudeAccuracy : 39|5@1+ (0.1,0) [0|2] "m" DEBUG
SG_ DCM_Altitude : 44|10@1+ (0.5,0) [0|400] "m" DEBUG
SG_ DCM_AltitudeAccuracy : 54|8@1+ (0.1,0) [0|20] "m" DEBUG

BO_ 218 DCM_GpsVelInfo: 8 DCM
SG_ DCM_VelocityStatus : 0|2@1+ (1,0) [0|3] "" DEBUG
SG_ DCM_VelocityNorth : 2|11@1+ (0.1,0) [0|120] "m/s" DEBUG
SG_ DCM_VelocityNorthAccuracy : 13|8@1+ (0.1,0) [0|20] "m/s" DEBUG
SG_ DCM_VelocityEast : 21|11@1+ (0.1,0) [0|120] "m/s" DEBUG
SG_ DCM_VelocityEastAccuracy : 32|8@1+ (0.1,0) [0|20] "m/s" DEBUG
SG_ DCM_VelocityDown : 40|11@1+ (0.1,0) [0|120] "m/s" DEBUG
SG_ DCM_VelocityDownAccuracy : 51|8@1+ (0.1,0) [0|20] "m/s" DEBUG

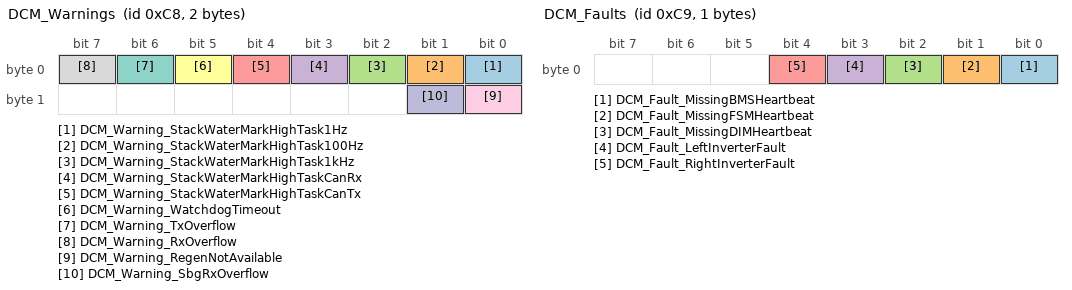
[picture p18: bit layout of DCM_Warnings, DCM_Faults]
BO_ 200 DCM_Warnings: 2 DCM
SG_ DCM_Warning_StackWaterMarkHighTask1Hz : 0|1@1+ (1,0) [0|1] "" DEBUG,Debug,Boot,INVR,PDM,FSM,DIM,BMS,INVL,DIM
SG_ DCM_Warning_StackWaterMarkHighTask100Hz : 1|1@1+ (1,0) [0|1] "" DEBUG,Debug,Boot,INVR,PDM,FSM,DIM,BMS,INVL,DIM
SG_ DCM_Warning_StackWaterMarkHighTask1kHz : 2|1@1+ (1,0) [0|1] "" DEBUG,Debug,Boot,INVR,PDM,FSM,DIM,BMS,INVL,DIM
SG_ DCM_Warning_StackWaterMarkHighTaskCanRx : 3|1@1+ (1,0) [0|1] "" DEBUG,Debug,Boot,INVR,PDM,FSM,DIM,BMS,INVL,DIM
SG_ DCM_Warning_StackWaterMarkHighTaskCanTx : 4|1@1+ (1,0) [0|1] "" DEBUG,Debug,Boot,INVR,PDM,FSM,DIM,BMS,INVL,DIM
SG_ DCM_Warning_WatchdogTimeout : 5|1@1+ (1,0) [0|1] "" DEBUG,Debug,Boot,INVR,PDM,FSM,DIM,BMS,INVL,DIM
SG_ DCM_Warning_TxOverflow : 6|1@1+ (1,0) [0|1] "" DEBUG,Debug,Boot,INVR,PDM,FSM,DIM,BMS,INVL,DIM
SG_ DCM_Warning_RxOverflow : 7|1@1+ (1,0) [0|1] "" DEBUG,Debug,Boot,INVR,PDM,FSM,DIM,BMS,INVL,DIM
SG_ DCM_Warning_RegenNotAvailable : 8|1@1+ (1,0) [0|1] "" DEBUG,Debug,Boot,INVR,PDM,FSM,DIM,BMS,INVL,DIM
SG_ DCM_Warning_SbgRxOverflow : 9|1@1+ (1,0) [0|1] "" DEBUG,Debug,Boot,INVR,PDM,FSM,DIM,BMS,INVL,DIM

BO_ 201 DCM_Faults: 1 DCM
SG_ DCM_Fault_MissingBMSHeartbeat : 0|1@1+ (1,0) [0|1] "" DEBUG,Debug,Boot,INVR,PDM,FSM,DIM,BMS,INVL
SG_ DCM_Fault_MissingFSMHeartbeat : 1|1@1+ (1,0) [0|1] "" DEBUG,Debug,Boot,INVR,PDM,FSM,DIM,BMS,INVL
SG_ DCM_Fault_MissingDIMHeartbeat : 2|1@1+ (1,0) [0|1] "" DEBUG,Debug,Boot,INVR,PDM,FSM,DIM,BMS,INVL
SG_ DCM_Fault_LeftInverterFault : 3|1@1+ (1,0) [0|1] "" DEBUG,Debug,Boot,INVR,PDM,FSM,DIM,BMS,INVL
SG_ DCM_Fault_RightInverterFault : 4|1@1+ (1,0) [0|1] "" DEBUG,Debug,Boot,INVR,PDM,FSM,DIM,BMS,INVL

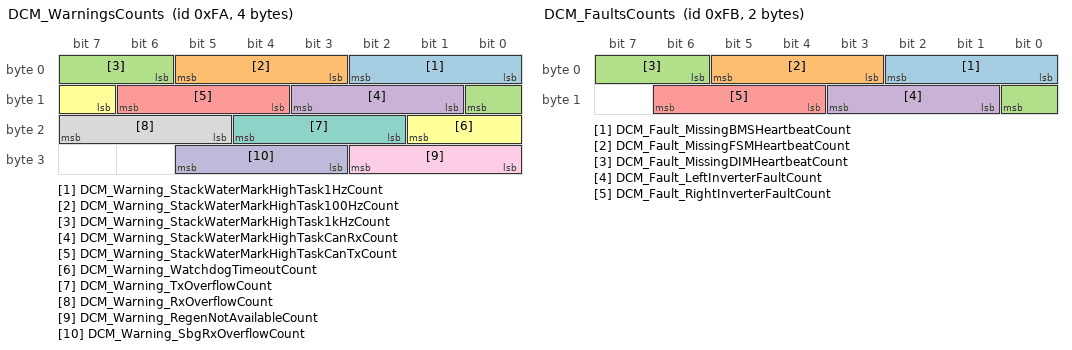
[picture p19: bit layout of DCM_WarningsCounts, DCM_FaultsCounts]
BO_ 250 DCM_WarningsCounts: 4 DCM
SG_ DCM_Warning_StackWaterMarkHighTask1HzCount : 0|3@1+ (1,0) [0|7] "" DEBUG
SG_ DCM_Warning_StackWaterMarkHighTask100HzCount : 3|3@1+ (1,0) [0|7] "" DEBUG
SG_ DCM_Warning_StackWaterMarkHighTask1kHzCount : 6|3@1+ (1,0) [0|7] "" DEBUG
SG_ DCM_Warning_StackWaterMarkHighTaskCanRxCount : 9|3@1+ (1,0) [0|7] "" DEBUG
SG_ DCM_Warning_StackWaterMarkHighTaskCanTxCount : 12|3@1+ (1,0) [0|7] "" DEBUG
SG_ DCM_Warning_WatchdogTimeoutCount : 15|3@1+ (1,0) [0|7] "" DEBUG
SG_ DCM_Warning_TxOverflowCount : 18|3@1+ (1,0) [0|7] "" DEBUG
SG_ DCM_Warning_RxOverflowCount : 21|3@1+ (1,0) [0|7] "" DEBUG
SG_ DCM_Warning_RegenNotAvailableCount : 24|3@1+ (1,0) [0|7] "" DEBUG
SG_ DCM_Warning_SbgRxOverflowCount : 27|3@1+ (1,0) [0|7] "" DEBUG

BO_ 251 DCM_FaultsCounts: 2 DCM
SG_ DCM_Fault_MissingBMSHeartbeatCount : 0|3@1+ (1,0) [0|7] "" DEBUG
SG_ DCM_Fault_MissingFSMHeartbeatCount : 3|3@1+ (1,0) [0|7] "" DEBUG
SG_ DCM_Fault_MissingDIMHeartbeatCount : 6|3@1+ (1,0) [0|7] "" DEBUG
SG_ DCM_Fault_LeftInverterFaultCount : 9|3@1+ (1,0) [0|7] "" DEBUG
SG_ DCM_Fault_RightInverterFaultCount : 12|3@1+ (1,0) [0|7] "" DEBUG

BA_DEF_  "BusType" STRING ;
BA_DEF_DEF_  "BusType" "CAN";

VAL_ 1109 Boot_BMS_Status 0 "BOOT_STATUS_APP_VALID" 1 "BOOT_STATUS_APP_INVALID" 2 "BOOT_STATUS_NO_APP";
VAL_ 1119 Boot_DCM_Status 0 "BOOT_STATUS_APP_VALID" 1 "BOOT_STATUS_APP_INVALID" 2 "BOOT_STATUS_NO_APP";
VAL_ 1129 Boot_FSM_Status 0 "BOOT_STATUS_APP_VALID" 1 "BOOT_STATUS_APP_INVALID" 2 "BOOT_STATUS_NO_APP";
VAL_ 1139 Boot_PDM_Status 0 "BOOT_STATUS_APP_VALID" 1 "BOOT_STATUS_APP_INVALID" 2 "BOOT_STATUS_NO_APP";
VAL_ 1149 Boot_DIM_Status 0 "BOOT_STATUS_APP_VALID" 1 "BOOT_STATUS_APP_INVALID" 2 "BOOT_STATUS_NO_APP";
VAL_ 1309 Boot_H7Dev_Status 0 "BOOT_STATUS_APP_VALID" 1 "BOOT_STATUS_APP_INVALID" 2 "BOOT_STATUS_NO_APP";
VAL_ 60 INVR_VsmState 0 "INVERTER_VSM_START_STATE" 1 "INVERTER_VSM_PRECHARGE_INIT_STATE" 2 "INVERTER_VSM_PRECHARGE_ACTIVE_STATE" 3 "INVERTER_VSM_PRECHARGE_COMPLETE_STATE" 4 "INVERTER_VSM_WAIT_STATE" 5 "INVERTER_VSM_READY_STATE" 6 "INVERTER_VSM_MOTOR_RUNNING_STATE" 7 "INVERTER_VSM_BLINK_FAULT_CODE_STATE" 14 "INVERTER_VSM_SHUTDOWN_IN_PROCESS" 15 "INVERTER_VSM_RECYCLE_POWER_STATE";
VAL_ 60 INVR_InverterState 0 "INVERTER_POWER_ON_STATE" 1 "INVERTER_STOP_STATE" 2 "INVERTER_OPEN_LOOP_STATE" 3 "INVERTER_CLOSED_LOOP_STATE" 4 "INVERTER_WAIT_STATE" 8 "INVERTER_IDLE_RUN_STATE" 9 "INVERTER_IDLE_STOP_STATE";
VAL_ 60 INVR_InverterActiveDischargeState 0 "INVERTER_ACTIVE_DISCHARGE_DISABLED" 1 "INVERTER_ACTIVE_DISCHARGE_ENABLED_WAITING" 2 "INVERTER_ACTIVE_DISCHARGE_PERFORMING_SPEED_CHECK" 3 "INVERTER_ACTIVE_DISCHARGE_OCCURING" 4 "INVERTER_ACTIVE_DISCHARGE_COMPLETED";
VAL_ 60 INVR_InverterCommandMode 0 "INVERTER_CAN_MODE" 1 "INVERTER_VSM_MODE";
VAL_ 60 INVR_InverterLockoutEnabled 0 "INVERTER_LOCKOUT_UNLOCKED" 1 "INVERTER_LOCKOUT_LOCKED";
VAL_ 60 INVR_DirectionCommand 0 "INVERTER_REVERSE_DIRECTION" 1 "INVERTER_FORWARD_DIRECTION";
VAL_ 83 INVR_CommandReadWrite 0 "INVERTER_READ_COMMAND" 1 "INVERTER_WRITE_COMMAND";
VAL_ 402 PDM_State 0 "PDM_INIT_STATE" 1 "PDM_DRIVE_STATE";
VAL_ 404 PDM_WatchdogTimeoutTaskName 0 "RTOS_TASK_1HZ" 1 "RTOS_TASK_100HZ" 2 "RTOS_TASK_1KHZ" 3 "RTOS_TASK_CAN_TX" 4 "RTOS_TASK_CAN_RX";
VAL_ 301 FSM_WatchdogTimeoutTaskName 0 "RTOS_TASK_1HZ" 1 "RTOS_TASK_100HZ" 2 "RTOS_TASK_1KHZ" 3 "RTOS_TASK_CAN_TX" 4 "RTOS_TASK_CAN_RX";
VAL_ 503 DIM_StartSwitch 0 "SWITCH_OFF" 1 "SWITCH_ON";
VAL_ 503 DIM_AuxSwitch 0 "SWITCH_OFF" 1 "SWITCH_ON";
VAL_ 505 DIM_WatchdogTimeoutTaskName 0 "RTOS_TASK_1HZ" 1 "RTOS_TASK_100HZ" 2 "RTOS_TASK_1KHZ" 3 "RTOS_TASK_CAN_TX" 4 "RTOS_TASK_CAN_RX";
VAL_ 100 BMS_State 0 "BMS_INIT_STATE" 1 "BMS_PRECHARGE_STATE" 2 "BMS_CHARGE_STATE" 3 "BMS_DRIVE_STATE" 4 "BMS_BALANCING_STATE" 5 "BMS_FAULT_STATE" 6 "BMS_INVERTER_ON_STATE";
VAL_ 104 BMS_WatchdogTimeoutTaskName 0 "RTOS_TASK_1HZ" 1 "RTOS_TASK_100HZ" 2 "RTOS_TASK_1KHZ" 3 "RTOS_TASK_CAN_TX" 4 "RTOS_TASK_CAN_RX";
VAL_ 105 BMS_ImdCondition 0 "IMD_CONDITION_SHORT_CIRCUIT" 1 "IMD_CONDITION_NORMAL" 2 "IMD_CONDITION_UNDERVOLTAGE_DETECTED" 3 "IMD_CONDITION_SST" 4 "IMD_CONDITION_DEVICE_ERROR" 5 "IMD_CONDITION_GROUND_FAULT" 6 "IMD_CONDITION_INVALID";
VAL_ 106 BMS_ImdActiveFrequency 0 "IMD_0Hz" 1 "IMD_10Hz" 2 "IMD_20Hz" 3 "IMD_30Hz" 4 "IMD_40Hz" 5 "IMD_50Hz";
VAL_ 112 BMS_AirPositive 0 "CONTACTOR_STATE_OPEN" 1 "CONTACTOR_STATE_CLOSED";
VAL_ 112 BMS_AirNegative 0 "CONTACTOR_STATE_OPEN" 1 "CONTACTOR_STATE_CLOSED";
VAL_ 112 BMS_PrechargeRelay 0 "CONTACTOR_STATE_OPEN" 1 "CONTACTOR_STATE_CLOSED";
VAL_ 10 INVL_VsmState 0 "INVERTER_VSM_START_STATE" 1 "INVERTER_VSM_PRECHARGE_INIT_STATE" 2 "INVERTER_VSM_PRECHARGE_ACTIVE_STATE" 3 "INVERTER_VSM_PRECHARGE_COMPLETE_STATE" 4 "INVERTER_VSM_WAIT_STATE" 5 "INVERTER_VSM_READY_STATE" 6 "INVERTER_VSM_MOTOR_RUNNING_STATE" 7 "INVERTER_VSM_BLINK_FAULT_CODE_STATE" 14 "INVERTER_VSM_SHUTDOWN_IN_PROCESS" 15 "INVERTER_VSM_RECYCLE_POWER_STATE";
VAL_ 10 INVL_InverterState 0 "INVERTER_POWER_ON_STATE" 1 "INVERTER_STOP_STATE" 2 "INVERTER_OPEN_LOOP_STATE" 3 "INVERTER_CLOSED_LOOP_STATE" 4 "INVERTER_WAIT_STATE" 8 "INVERTER_IDLE_RUN_STATE" 9 "INVERTER_IDLE_STOP_STATE";
VAL_ 10 INVL_InverterActiveDischargeState 0 "INVERTER_ACTIVE_DISCHARGE_DISABLED" 1 "INVERTER_ACTIVE_DISCHARGE_ENABLED_WAITING" 2 "INVERTER_ACTIVE_DISCHARGE_PERFORMING_SPEED_CHECK" 3 "INVERTER_ACTIVE_DISCHARGE_OCCURING" 4 "INVERTER_ACTIVE_DISCHARGE_COMPLETED";
VAL_ 10 INVL_InverterCommandMode 0 "INVERTER_CAN_MODE" 1 "INVERTER_VSM_MODE";
VAL_ 10 INVL_InverterLockoutEnabled 0 "INVERTER_LOCKOUT_UNLOCKED" 1 "INVERTER_LOCKOUT_LOCKED";
VAL_ 10 INVL_DirectionCommand 0 "INVERTER_REVERSE_DIRECTION" 1 "INVERTER_FORWARD_DIRECTION";
VAL_ 33 INVL_CommandReadWrite 0 "INVERTER_READ_COMMAND" 1 "INVERTER_WRITE_COMMAND";
VAL_ 203 DCM_State 0 "DCM_INIT_STATE" 1 "DCM_DRIVE_STATE";
VAL_ 32 DCM_LeftInverterDirectionCommand 0 "INVERTER_REVERSE_DIRECTION" 1 "INVERTER_FORWARD_DIRECTION";
VAL_ 82 DCM_RightInverterDirectionCommand 0 "INVERTER_REVERSE_DIRECTION" 1 "INVERTER_FORWARD_DIRECTION";
VAL_ 204 DCM_WatchdogTimeoutTaskName 0 "RTOS_TASK_1HZ" 1 "RTOS_TASK_100HZ" 2 "RTOS_TASK_1KHZ" 3 "RTOS_TASK_CAN_TX" 4 "RTOS_TASK_CAN_RX";
VAL_ 217 DCM_PositionStatus 0 "Solution_Computed" 1 "Insufficent_Readings" 2 "Internal_Error" 3 "Limit_Exceeded";
VAL_ 218 DCM_VelocityStatus 0 "Solution_Computed" 1 "Insufficent_Readings" 2 "Internal_Error" 3 "Limit_Exceeded";
